VERSION "BYD N3 (SA6) subset of ADC V2.8.0 20251225 platform matrices"

NS_ :

BS_:

BU_: XXX

BO_ 109 EPS_0x06D: 64 EPS
SG_ Counter_06D_S : 0|16@1+ (1,0) [0E-008|65535.00000000] "" ADC
SG_ Checksum_06D_S : 16|16@1+ (1,0) [0E-008|65535.00000000] "" ADC
SG_ EPS_AgCtrlAvl : 32|2@1+ (1,0) [0E-008|3.00000000] "" ADC
SG_ EPS_AgCtrlSts : 34|2@1+ (1,0) [0E-008|3.00000000] "" ADC
SG_ EPS_TqCtrlAvl : 36|2@1+ (1,0) [0E-008|3.00000000] "" ADC
SG_ EPS_TqCtrlSts : 38|2@1+ (1,0) [0E-008|3.00000000] "" ADC
SG_ EPS_LdwWarnAvl : 40|2@1+ (1,0) [0E-008|3.00000000] "" ADC
SG_ EPS_LdwWarnSts : 42|2@1+ (1,0) [0E-008|3.00000000] "" ADC
SG_ EPS_SteerPinionAg : 44|16@1- (0.1000000000000000055511151231257827021181583404541015625,0) [-720.00000000|720.00000000] "deg" ADC
SG_ EPS_SteerPinionAgVld : 60|1@1+ (1,0) [0E-008|1.00000000] "" ADC
SG_ EPS_SteerPinionAgRat : 61|15@1- (0.1000000000000000055511151231257827021181583404541015625,0) [-1500.00000000|1500.00000000] "deg/s" ADC
SG_ EPS_SteerPinionAgRatVld : 76|1@1+ (1,0) [0E-008|1.00000000] "" ADC
SG_ EPS_SteerWheelAg : 77|16@1- (0.1000000000000000055511151231257827021181583404541015625,0) [-720.00000000|720.00000000] "deg" ADC
SG_ EPS_SteerWheelAgVld : 93|1@1+ (1,0) [0E-008|1.00000000] "" ADC
SG_ EPS_SteerWheelAgRat : 94|15@1- (0.1000000000000000055511151231257827021181583404541015625,0) [-1500.00000000|1500.00000000] "deg/s" ADC
SG_ EPS_SteerWheelAgRatVld : 109|1@1+ (1,0) [0E-008|1.00000000] "" ADC
SG_ EPS_AsscMotCrtTq : 110|11@1- (0.0200000000000000004163336342344337026588618755340576171875,0) [-20.00000000|20.00000000] "Nm" ADC
SG_ EPS_AsscMotCrtTqVld : 121|1@1+ (1,0) [0E-008|1.00000000] "" ADC
SG_ EPS_DrvrSteerTq : 122|11@1- (0.0200000000000000004163336342344337026588618755340576171875,0) [-20.00000000|20.00000000] "Nm" ADC
SG_ EPS_DrvrSteerTqVld : 133|1@1+ (1,0) [0E-008|1.00000000] "-" ADC
SG_ EPS_DrvrSteerTqFlt : 134|11@1- (0.0200000000000000004163336342344337026588618755340576171875,0) [-20.00000000|20.00000000] "Nm" ADC
SG_ EPS_DrvrSteerTqFltVld : 145|1@1+ (1,0) [0E-008|1.00000000] "-" ADC
SG_ EPS_SteerDrvrOvrd : 146|1@1+ (1,0) [0E-008|1.00000000] "" ADC
SG_ EPS_SteerDrvrOvrdVld : 147|1@1+ (1,0) [0E-008|1.00000000] "" ADC
SG_ EPS_ADCReqErrorFb : 148|3@1+ (1,0) [0E-008|7.00000000] "" ADC
SG_ EPS_AbortFb : 151|3@1+ (1,0) [0E-008|7.00000000] "" ADC
SG_ EPS_SteerMod : 154|3@1+ (1,0) [0E-008|7.00000000] "" ADC
SG_ EpsFltSts : 157|2@1+ (1,0) [0E-008|3.00000000] "" ADC
SG_ EPS_BoostMod : 159|2@1+ (1,0) [0E-008|3.00000000] "" ADC
SG_ EPS_TasCalSts : 161|1@1+ (1,0) [0E-008|1.00000000] "" ADC
SG_ EPS_Tq1 : 162|11@1- (0.0200000000000000004163336342344337026588618755340576171875,0) [-20.00000000|20.00000000] "Nm" ADC
SG_ EPS_Tq2 : 173|11@1- (0.0200000000000000004163336342344337026588618755340576171875,0) [-20.00000000|20.00000000] "Nm" ADC
SG_ EPS_Fastbattery_Temperature : 184|11@1+ (0.200000000000000011102230246251565404236316680908203125,-60) [-60.00000000|349.40000000] "°" ADC
BO_ 268 IPB_0x10C: 64 IPB
SG_ Checksum_10C_S : 0|16@1+ (1,0) [0E-008|65535.00000000] "" ADC
SG_ Counter_10C_S : 16|16@1+ (1,0) [0E-008|65535.00000000] "" ADC
SG_ Vehicle_speed : 35|12@1+ (0.0687500000000000055511151231257827021181583404541015625,0) [0E-008|281.46250000] "km/h" ADC
SG_ VehicleSpeed_Status : 47|1@1+ (1,0) [0E-008|1.00000000] "" ADC
SG_ WheelSpeed_FL : 48|12@1+ (0.0687500000000000055511151231257827021181583404541015625,0) [0E-008|281.46250000] "km/h" ADC
SG_ WheelSpeed_FR : 60|12@1+ (0.0687500000000000055511151231257827021181583404541015625,0) [0E-008|281.46250000] "km/h" ADC
SG_ WheelSpeed_RL : 72|12@1+ (0.0687500000000000055511151231257827021181583404541015625,0) [0E-008|281.46250000] "km/h" ADC
SG_ WheelSpeed_RR : 84|12@1+ (0.0687500000000000055511151231257827021181583404541015625,0) [0E-008|281.46250000] "km/h" ADC
SG_ WheelSpeed_FR_Status : 96|1@1+ (1,0) [0E-008|1.00000000] "" ADC
SG_ WheelSpeed_FL_Status : 97|1@1+ (1,0) [0E-008|1.00000000] "" ADC
SG_ WheelSpeed_RR_Status : 98|1@1+ (1,0) [0E-008|1.00000000] "" ADC
SG_ WheelSpeed_RL_Status : 99|1@1+ (1,0) [0E-008|1.00000000] "" ADC
SG_ RRWheelDriveDirection : 100|2@1+ (1,0) [0E-008|3.00000000] "" ADC
SG_ RLWheelDriveDirection : 102|2@1+ (1,0) [0E-008|3.00000000] "" ADC
SG_ FRWheelDriveDirection : 104|2@1+ (1,0) [0E-008|3.00000000] "" ADC
SG_ FLWheelDriveDirection : 106|2@1+ (1,0) [0E-008|3.00000000] "" ADC
SG_ FLWheelDriveDirectionStatus : 108|1@1+ (1,0) [0E-008|1.00000000] "" ADC
SG_ FRWheelDriveDirectionStatus : 109|1@1+ (1,0) [0E-008|1.00000000] "" ADC
SG_ RLWheelDriveDirectionStatus : 110|1@1+ (1,0) [0E-008|1.00000000] "" ADC
SG_ RRWheelDriveDirectionStatus : 111|1@1+ (1,0) [0E-008|1.00000000] "" ADC
SG_ FLWheelPulseCounter : 112|10@1+ (1,0) [0E-008|1022.00000000] "" ADC
SG_ FRWheelPulseCounter : 122|10@1+ (1,0) [0E-008|1022.00000000] "" ADC
SG_ RLWheelPulseCounter : 132|10@1+ (1,0) [0E-008|1022.00000000] "" ADC
SG_ RRWheelPulseCounter : 142|10@1+ (1,0) [0E-008|1022.00000000] "" ADC
SG_ RRWheelPulseCounterValidity : 152|1@1+ (1,0) [0E-008|1.00000000] "" ADC
SG_ RLWheelPulseCounterValidity : 153|1@1+ (1,0) [0E-008|1.00000000] "" ADC
SG_ FRWheelPulseCounterValidity : 154|1@1+ (1,0) [0E-008|1.00000000] "" ADC
SG_ FLWheelPulseCounterValidity : 155|1@1+ (1,0) [0E-008|1.00000000] "" ADC
SG_ EBD_Active : 156|1@1+ (1,0) [0E-008|1.00000000] "" ADC
SG_ EBD_Fault : 157|1@1+ (1,0) [0E-008|1.00000000] "" ADC
SG_ ABS_Active : 158|1@1+ (1,0) [0E-008|1.00000000] "" ADC
SG_ ABS_Fault : 159|1@1+ (1,0) [0E-008|1.00000000] "" ADC
SG_ VDC_Active : 160|1@1+ (1,0) [0E-008|1.00000000] "" ADC
SG_ VDC_Fault : 161|1@1+ (1,0) [0E-008|1.00000000] "" ADC
SG_ ESP_OFF : 162|1@1+ (1,0) [0E-008|1.00000000] "" ADC
SG_ ESP_Active : 163|1@1+ (1,0) [0E-008|1.00000000] "" ADC
SG_ TCS_Fault : 164|1@1+ (1,0) [0E-008|1.00000000] "" ADC
SG_ AVH_CtrlStatus : 166|2@1+ (1,0) [0E-008|3.00000000] "" ADC
SG_ LFI_Longitudinal_Torque_Interface_Function_Execution_Estimate_S : 168|16@1+ (1,-30000) [-30000.00000000|30000.00000000] "" ADC
SG_ DiDyna_Estimate_Yaw_Torque : 184|16@1+ (2,-40000) [-40000.00000000|40000.00000000] "" ADC
SG_ TCS_Active : 209|1@1+ (1,0) [0E-008|1.00000000] "" ADC
SG_ CCO_Active : 210|2@1+ (1,0) [0E-008|3.00000000] "" ADC
SG_ HDC_CtrlStatus : 222|2@1+ (1,0) [0E-008|3.00000000] "" ADC
SG_ Yaw_Rate : 225|12@1+ (0.0021326029999999998425230796073037708993069827556610107421875,-2.094300000000000050448534238967113196849822998046875) [-2.09430000|2.09430000] "rad/s" ADC
SG_ Yaw_Rate_Offset : 237|12@1+ (0.0021326029999999998425230796073037708993069827556610107421875,-0.13000000000000000444089209850062616169452667236328125) [-0.13000000|0.13000000] "rad/s" ADC
SG_ Yaw_Rate_Status : 249|1@1+ (1,0) [0E-008|1.00000000] "" ADC
SG_ AX : 250|12@1+ (0.02712673599999999851650755999799002893269062042236328125,-21.592999999999999971578290569595992565155029296875) [-21.59300000|21.59300000] "m/s�0�5" ADC
SG_ AX_Offset : 262|12@1+ (0.02712673599999999851650755999799002893269062042236328125,-21.592999999999999971578290569595992565155029296875) [-21.59300000|21.59300000] "m/s�0�5" ADC
SG_ AXstatus : 274|1@1+ (1,0) [0E-008|1.00000000] "" ADC
SG_ AY : 275|12@1+ (0.02712673599999999851650755999799002893269062042236328125,-21.592999999999999971578290569595992565155029296875) [-21.59300000|21.59300000] "m/s�0�5" ADC
SG_ AYOffset : 287|12@1+ (0.02712673599999999851650755999799002893269062042236328125,-21.592999999999999971578290569595992565155029296875) [-21.59300000|21.59300000] "m/s�0�5" ADC
SG_ AYstatus : 299|1@1+ (1,0) [0E-008|1.00000000] "" ADC
SG_ AutomaticBrakingAvailable : 303|1@1+ (1,0) [0E-008|1.00000000] "" ADC
SG_ AutomaticBrakingActive : 304|1@1+ (1,0) [0E-008|1.00000000] "" ADC
SG_ IPB_InputRodStroke : 306|10@1+ (0.05000000000000000277555756156289135105907917022705078125,-5) [-5.00000000|46.15000000] "mm" ADC
SG_ IPB_InputRodStroke_Status : 316|1@1+ (1,0) [0E-008|1.00000000] "" ADC
SG_ FWA_warning : 318|2@1+ (1,0) [0E-008|3.00000000] "" ADC
SG_ DiDyna_LDI_Active : 320|1@1+ (1,0) [0E-008|1.00000000] "" ADC
SG_ Basc_FA : 323|1@1+ (1,0) [0E-008|1.00000000] "" ADC
SG_ Basc_RA : 324|1@1+ (1,0) [0E-008|1.00000000] "" ADC
SG_ AWBavailable : 325|1@1+ (1,0) [0E-008|1.00000000] "" ADC
SG_ AWBactive : 326|1@1+ (1,0) [0E-008|1.00000000] "" ADC
SG_ PrefillAvailable : 330|1@1+ (1,0) [0E-008|1.00000000] "" ADC
SG_ PrefillActive : 331|1@1+ (1,0) [0E-008|1.00000000] "" ADC
SG_ ESC_BrkTqCtrlAvlDriving : 335|1@1+ (1,0) [0E-008|1.00000000] "" ADC
SG_ ESC_BrkTqCtrlAvlParking : 336|2@1+ (1,0) [0E-008|3.00000000] "" ADC
SG_ ESC_BrkTqCtrlActv : 338|2@1+ (1,0) [0E-008|3.00000000] "" ADC
SG_ ESC_AebBrkTqAvl : 340|1@1+ (1,0) [0E-008|1.00000000] "" ADC
SG_ IPB_BRAKE_PEDAL_STARUS : 349|2@1+ (1,0) [0E-008|3.00000000] "" ADC
SG_ IPB_SimulatorPressure_Sts : 351|1@1+ (1,0) [0E-008|1.00000000] "" ADC
SG_ IPB_SimulatorPressure : 352|12@1+ (0.299999999999999988897769753748434595763683319091796875,-5) [-5.00000000|301.90000000] "bar" ADC
SG_ IPB_PlungerPressure_status : 364|1@1+ (1,0) [0E-008|1.00000000] "" ADC
SG_ DiDyna_LDI_Available : 365|1@1+ (1,0) [0E-008|1.00000000] "" ADC
SG_ IPB_PlungerPressure : 366|12@1+ (0.299999999999999988897769753748434595763683319091796875,-5) [-5.00000000|301.90000000] "bar" ADC
SG_ Ve_Target_Fdback_Tor_Flag_S : 378|2@1+ (1,0) [0E-008|3.00000000] "" ADC
SG_ Ve_Target_Fdback_Tor_S : 380|14@1+ (1,-6000) [-6000.00000000|6000.00000000] "NM" ADC
SG_ ESC_DrvrTqDes : 408|16@1+ (1,-30000) [-30000.00000000|-30000.00000000] "" ADC
SG_ ESC_HydBrkActvTq : 424|16@1+ (1,-30000) [-30000.00000000|-30000.00000000] "" ADC
SG_ MMotTarFast_FA : 440|16@1+ (1,-12000) [-12000.00000000|12000.00000000] "" ADC
SG_ MMotTarFast_RA : 456|16@1+ (1,-12000) [-12000.00000000|12000.00000000] "" ADC
SG_ MMotInc_FA_S : 472|14@1+ (1,-6000) [-6000.00000000|6000.00000000] "" ADC
SG_ MMotInc_RA_S : 486|14@1+ (1,-6000) [-6000.00000000|6000.00000000] "" ADC
SG_ IPB_BrakeOverride_val : 500|1@1+ (1,0) [0E-008|1.00000000] "" ADC
SG_ IPB_BrakeOverride : 501|1@1+ (1,0) [0E-008|1.00000000] "" ADC
SG_ HHC_Active : 503|1@1+ (1,0) [0E-008|1.00000000] "" ADC
SG_ ESC_AebBrkTqActv : 504|1@1+ (1,0) [0E-008|1.00000000] "" ADC
SG_ VehicleStandstill : 505|2@1+ (1,0) [0E-008|3.00000000] "" ADC
SG_ BMsr_FA_S : 509|1@1+ (1,0) [0E-008|1.00000000] "" ADC
SG_ BMsr_RA_S : 510|1@1+ (1,0) [0E-008|1.00000000] "" ADC
BO_ 90 VCU_0x05A: 64 VCU
SG_ Checksum_05A_S : 0|16@1+ (1,0) [0E-008|65535.00000000] "" ADC
SG_ Counter_05A_S : 16|16@1+ (1,0) [0E-008|65535.00000000] "" ADC
SG_ VCU_ActPedlPosnVld : 32|1@1+ (1,0) [0E-008|1.00000000] "" ADC
SG_ VCU_AccrPedlPosnVld : 33|1@1+ (1,0) [0E-008|1.00000000] "" ADC
SG_ VCU_DrvrAccrPedlOvrd : 34|1@1+ (1,0) [0E-008|1.00000000] "" ADC
SG_ VCU_DrvrAccrPedlOvrdVLD : 35|1@1+ (1,0) [0E-008|1.00000000] "" ADC
SG_ VCU_VehWhlActTqVld : 36|1@1+ (1,0) [0E-008|1.00000000] "" ADC
SG_ VCU_FrntWhlReqTqVld : 37|1@1+ (1,0) [0E-008|1.00000000] "" ADC
SG_ VCU_ReWhlReqTqVld : 38|1@1+ (1,0) [0E-008|1.00000000] "" ADC
SG_ VCU_VehWhlReqTqVld : 39|1@1+ (1,0) [0E-008|1.00000000] "" ADC
SG_ VCU_DriverTorqueDesired : 40|16@1- (1,0) [-32768.00000000|32767.00000000] "" ADC
SG_ VCU_OrgDriverTorqueDesired : 56|16@1- (1,0) [-32768.00000000|32767.00000000] "" ADC
SG_ VCU_VehWhlActTq : 72|16@1- (1,0) [-32768.00000000|32767.00000000] "" ADC
SG_ VCU_FrntWhlReqTq : 88|16@1- (1,0) [-32768.00000000|32767.00000000] "" ADC
SG_ VCU_ReWhlReqTq : 104|16@1- (1,0) [-32768.00000000|32767.00000000] "" ADC
SG_ VCU_VehWhlReqTq : 120|16@1- (1,0) [-32768.00000000|32767.00000000] "" ADC
SG_ VCU_PtRgnTqMax : 136|16@1- (1,0) [-32768.00000000|32767.00000000] "" ADC
SG_ VCU_PtElecTqMax : 152|16@1- (1,0) [-32768.00000000|32767.00000000] "" ADC
SG_ VCU_MotorRegenTorqueLmtInD : 168|13@1- (1,0) [-4096.00000000|4095.00000000] "" ADC
SG_ VCU_PtRgnTqMaxVld : 181|1@1+ (1,0) [0E-008|1.00000000] "" ADC
SG_ VCU_PtElecTqMaxVld : 182|1@1+ (1,0) [0E-008|1.00000000] "" ADC
SG_ VCU_MotorRegenTrqLmtInDValid : 183|1@1+ (1,0) [0E-008|1.00000000] "" ADC
SG_ VCU_PtTqAvl : 184|2@1+ (1,0) [0E-008|3.00000000] "" ADC
SG_ VCU_PtTqActvSts : 186|1@1+ (1,0) [0E-008|1.00000000] "" ADC
SG_ VCU_MCUModActvSt : 187|2@1+ (1,0) [0E-008|3.00000000] "" ADC
SG_ VCU_MCUBlkSt : 189|3@1+ (1,0) [0E-008|7.00000000] "" ADC
SG_ VCU_SpdSvModAvl : 192|1@1+ (1,0) [0E-008|1.00000000] "" ADC
SG_ VCU_MCUStandstill : 193|1@1+ (1,0) [0E-008|1.00000000] "" ADC
SG_ VCU_MCUSpdSVModFlt : 194|3@1+ (1,0) [0E-008|7.00000000] "" ADC
SG_ VCU_ErrorFb : 197|4@1+ (1,0) [0E-008|15.00000000] "" ADC
SG_ VCU_MCUReqTq : 201|14@1- (1,0) [-5001.00000000|5001.00000000] "" ADC
SG_ Rnk_efc_flg_hw : 215|1@1+ (1,0) [0E-008|1.00000000] "" ADC
SG_ VCU_MCUActRUnfilteredRodSpd : 216|16@1- (1,0) [-30001.00000000|3001.00000000] "rpm" ADC
SG_ VCU_MCUActFUnfilteredRodSpd : 232|16@1- (1,0) [-30001.00000000|3001.00000000] "rpm" ADC
SG_ Rnk_hw : 248|4@1+ (1,0) [0E-008|15.00000000] "" ADC
SG_ F_mot_spd_err_flg_hw : 252|1@1+ (1,0) [0E-008|1.00000000] "" ADC
SG_ R_mot_spd_err_hw : 253|1@1+ (1,0) [0E-008|1.00000000] "" ADC
SG_ Faxis_act_tq_efc_flg_hw : 254|1@1+ (1,0) [0E-008|1.00000000] "" ADC
SG_ R_mot_fac_tq_sts_hw : 255|1@1+ (1,0) [0E-008|1.00000000] "" ADC
SG_ Act_acce_pedl_perc_hw : 256|8@1+ (1,0) [0E-008|100.00000000] "" ADC
SG_ F_mot_spd_hw : 264|16@1+ (1,-30000) [-30000.00000000|30000.00000000] "" ADC
SG_ R_mot_spd_hw : 280|16@1+ (1,-30000) [-30000.00000000|30000.00000000] "" ADC
SG_ Act_drv_mod_hw : 296|8@1+ (1,0) [0E-008|255.00000000] "" ADC
SG_ Virt_acce_pedl_perc_hw : 304|8@1+ (1,0) [0E-008|100.00000000] "" ADC
SG_ Faxis_act_tq_hw : 312|16@1+ (1,-12000) [-12000.00000000|12000.00000000] "" ADC
SG_ R_axis_fac_tq_hw : 328|16@1+ (1,-12000) [-12000.00000000|12000.00000000] "" ADC
SG_ Ok_lamp_hw : 344|2@1+ (1,0) [0E-008|3.00000000] "" ADC
SG_ VCU_DriveReady : 346|2@1+ (1,0) [0E-008|3.00000000] "" ADC
SG_ Bsg_Gmcu_start_eng_sts : 348|2@1+ (1,0) [0E-008|3.00000000] "" ADC
SG_ VCU_REQ_ADAS_SPC_FUN_STOP_EN_S : 350|2@1+ (1,0) [0E-008|3.00000000] "" ADC
SG_ FL_mot_whl_act_tq_S : 352|16@1- (1,0) [-32768.00000000|32767.00000000] "Nm" ADC
SG_ FR_mot_whl_act_tq_S : 368|16@1- (1,0) [-32768.00000000|32767.00000000] "Nm" ADC
SG_ RL_mot_whl_act_tq_S : 384|16@1- (1,0) [-32768.00000000|32767.00000000] "Nm" ADC
SG_ RR_mot_whl_act_tq_S : 400|16@1- (1,0) [-32768.00000000|32767.00000000] "Nm" ADC
SG_ FL_mot_spd_S : 416|16@1- (1,0) [-32768.00000000|32767.00000000] "Nm" ADC
SG_ FR_mot_spd_S : 432|16@1- (1,0) [-32768.00000000|32767.00000000] "Nm" ADC
SG_ RL_mot_spd_S : 448|16@1- (1,0) [-32768.00000000|32767.00000000] "Nm" ADC
SG_ RR_mot_spd_S : 464|16@1- (1,0) [-32768.00000000|32767.00000000] "Nm" ADC
SG_ FL_mot_whl_act_tq_efc_flg_S : 480|1@1+ (1,0) [0E-008|1.00000000] "" ADC
SG_ FR_mot_whl_act_tq_efc_flg_S : 481|1@1+ (1,0) [0E-008|1.00000000] "" ADC
SG_ LR_mot_whl_act_tq_efc_flg_S : 482|1@1+ (1,0) [0E-008|1.00000000] "" ADC
SG_ RR_mot_whl_act_tq_efc_flg_S : 483|1@1+ (1,0) [0E-008|1.00000000] "" ADC
SG_ FL_mot_spd_efc_flg_S : 484|1@1+ (1,0) [0E-008|1.00000000] "" ADC
SG_ FR_mot_spd_efc_flg_S : 485|1@1+ (1,0) [0E-008|1.00000000] "" ADC
SG_ RL_mot_spd_efc_flg_S : 486|1@1+ (1,0) [0E-008|1.00000000] "" ADC
SG_ RR_mot_spd_efc_flg_S : 487|1@1+ (1,0) [0E-008|1.00000000] "" ADC
SG_ AI_Drift_Control_Mode_Response_State_S : 488|1@1+ (1,0) [0E-008|1.00000000] "" ADC
SG_ E4_ParkEPS_Contrl_Learning_S : 496|2@1+ (1,0) [0E-008|3.00000000] "" ADC
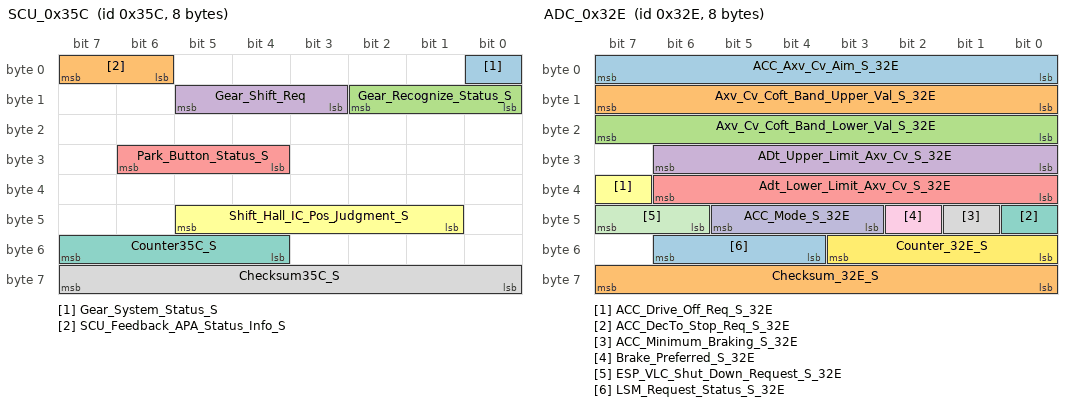
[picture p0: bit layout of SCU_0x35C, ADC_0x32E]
BO_ 860 SCU_0x35C: 8 SCU
SG_ Gear_System_Status_S : 0|1@1+ (1,0) [0E-008|1.00000000] "" ADC
SG_ SCU_Feedback_APA_Status_Info_S : 6|2@1+ (1,0) [0E-008|3.00000000] "" ADC
SG_ Gear_Recognize_Status_S : 8|3@1+ (1,0) [0E-008|7.00000000] "" ADC
SG_ Gear_Shift_Req : 11|3@1+ (1,0) [0E-008|7.00000000] "" ADC
SG_ Park_Button_Status_S : 28|3@1+ (1,0) [0E-008|7.00000000] "" ADC
SG_ Shift_Hall_IC_Pos_Judgment_S : 41|5@1+ (1,0) [0E-008|31.00000000] "" ADC
SG_ Counter35C_S : 52|4@1+ (1,0) [0E-008|15.00000000] "Nm" ADC
SG_ Checksum35C_S : 56|8@1+ (1,0) [0E-008|255.00000000] "度" ADC
BO_ 813 ADC_0x32D: 8 ADC
SG_ Set_Speed_S : 0|9@1+ (1,0) [0E-008|255.50000000] "" Left_BCM,Media,INS,SRS,FCR
SG_ Obj_Valid_S : 9|1@1+ (1,0) [0E-008|1.00000000] "" Left_BCM,Media,INS,SRS,FCR
SG_ Tau_Gap_Set_S : 10|3@1+ (1,0) [0E-008|7.00000000] "" Left_BCM,Media,INS,SRS,FCR
SG_ Dx_Tar_Obj_S : 13|3@1+ (1,0) [0E-008|7.00000000] "" Left_BCM,Media,INS,SRS,FCR
SG_ PCW_Pre_Warning_S : 16|1@1+ (1,0) [0E-008|1.00000000] "" Left_BCM,Media,INS,SRS,FCR
SG_ PCW_Latent_Warning_S : 17|1@1+ (1,0) [0E-008|1.00000000] "" Left_BCM,Media,INS,SRS,FCR
SG_ PCW_State_S : 18|1@1+ (1,0) [0E-008|1.00000000] "" Left_BCM,Media,INS,SRS,FCR
SG_ ACC_Mode_Display_S : 19|3@1+ (1,0) [0E-008|7.00000000] "" Left_BCM,Media,INS,SRS,FCR
SG_ ACC_State_S : 22|1@1+ (1,0) [0E-008|1.00000000] "" Left_BCM,Media,INS,SRS,FCR
SG_ Take_Over_Req_S : 23|1@1+ (1,0) [0E-008|1.00000000] "" Left_BCM,Media,INS,SRS,FCR
SG_ Speed_Unit_Set_S2 : 24|2@1+ (1,0) [0E-008|3.00000000] "" Left_BCM,Media,INS,SRS,FCR
SG_ CCR_AEB_Error_S : 26|1@1+ (1,0) [0E-008|1.00000000] "" Left_BCM,Media,INS,SRS,FCR
SG_ ACC_Text_Info_For_Driver_S : 27|5@1+ (1,0) [0E-008|31.00000000] "" Left_BCM,Media,INS,SRS,FCR
SG_ CCR_FCW_Error_S : 32|1@1+ (1,0) [0E-008|1.00000000] "" Left_BCM,Media,INS,SRS,FCR
SG_ Pedestrian_FCW_Brak_Error_S : 33|1@1+ (1,0) [0E-008|1.00000000] "" Left_BCM,Media,INS,SRS,FCR
SG_ Acute_Warning_S : 35|1@1+ (1,0) [0E-008|1.00000000] "" Left_BCM,Media,INS,SRS,FCR
SG_ AEB_State_S : 36|1@1+ (1,0) [0E-008|1.00000000] "" Left_BCM,Media,INS,SRS,FCR
SG_ PCWLevelState : 37|2@1+ (1,0) [0E-008|3.00000000] "" Left_BCM,Media,INS,SRS,FCR
SG_ Front_radar_FCTB_Warning : 41|3@1+ (1,0) [0E-008|7.00000000] "" Left_BCM,Media,INS,SRS,FCR
SG_ ACC_Mode_Display1_S : 44|4@1+ (1,0) [0E-008|15.00000000] "" Left_BCM,Media,INS,SRS,FCR
SG_ Counter_32D_S : 48|4@1+ (1,0) [0E-008|15.00000000] "" Left_BCM,Media,INS,SRS,FCR
SG_ ELK_Assemble_Status_S : 52|1@1+ (1,0) [0E-008|1.00000000] "" Left_BCM,Media,INS,SRS,FCR
SG_ MRR_Modulation_Status : 54|2@1+ (1,0) [0E-008|3.00000000] "" Left_BCM,Media,INS,SRS,FCR
SG_ Checksum_32D_S : 56|8@1+ (1,0) [0E-008|255.00000000] "" Left_BCM,Media,INS,SRS,FCR
BO_ 814 ADC_0x32E: 8 ADC
SG_ ACC_Axv_Cv_Aim_S_32E : 0|8@1+ (0.05000000000000000277555756156289135105907917022705078125,-7) [-7.00000000|5.75000000] "m/s2" VCU,IPB
SG_ Axv_Cv_Coft_Band_Upper_Val_S_32E : 8|8@1+ (0.05000000000000000277555756156289135105907917022705078125,-7) [-7.00000000|5.75000000] "m/s2" VCU,IPB
SG_ Axv_Cv_Coft_Band_Lower_Val_S_32E : 16|8@1+ (0.05000000000000000277555756156289135105907917022705078125,-7) [-7.00000000|5.75000000] "m/s2" VCU,IPB
SG_ ADt_Upper_Limit_Axv_Cv_S_32E : 24|7@1+ (0.200000000000000011102230246251565404236316680908203125,0) [0E-008|16.00000000] "m/s3" VCU,IPB
SG_ Adt_Lower_Limit_Axv_Cv_S_32E : 32|7@1+ (0.200000000000000011102230246251565404236316680908203125,-16) [-16.00000000|0E-008] "m/s3" VCU,IPB
SG_ ACC_Drive_Off_Req_S_32E : 39|1@1+ (1,0) [0E-008|1.00000000] "" VCU,IPB
SG_ ACC_DecTo_Stop_Req_S_32E : 40|1@1+ (1,0) [0E-008|1.00000000] "" VCU,IPB
SG_ ACC_Minimum_Braking_S_32E : 41|1@1+ (1,0) [0E-008|1.00000000] "" VCU,IPB
SG_ Brake_Preferred_S_32E : 42|1@1+ (1,0) [0E-008|1.00000000] "" VCU,IPB
SG_ ACC_Mode_S_32E : 43|3@1+ (1,0) [0E-008|7.00000000] "" VCU,IPB,SRS
SG_ ESP_VLC_Shut_Down_Request_S_32E : 46|2@1+ (1,0) [0E-008|3.00000000] "" VCU,IPB
SG_ Counter_32E_S : 48|4@1+ (1,0) [0E-008|15.00000000] "" VCU,IPB
SG_ LSM_Request_Status_S_32E : 52|3@1+ (1,0) [0E-008|7.00000000] "" VCU,IPB
SG_ Checksum_32E_S : 56|8@1+ (1,0) [0E-008|255.00000000] "" VCU,IPB
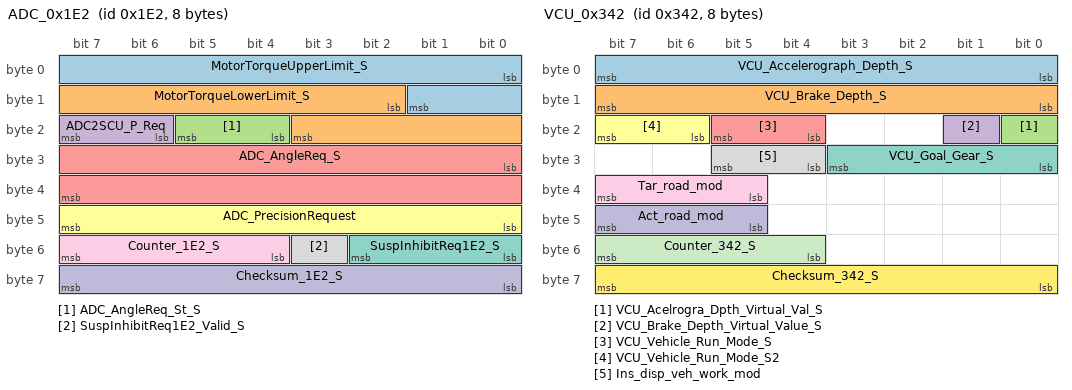
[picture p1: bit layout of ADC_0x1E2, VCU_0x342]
BO_ 482 ADC_0x1E2: 8 ADC
SG_ MotorTorqueUpperLimit_S : 0|10@1+ (0.01000000000000000020816681711721685132943093776702880859375,0) [0E-008|5.00000000] "" Left_BCM,VCU,DiSus
SG_ MotorTorqueLowerLimit_S : 10|10@1- (0.01000000000000000020816681711721685132943093776702880859375,0) [-5.00000000|0E-008] "" Left_BCM,VCU,DiSus
SG_ ADC_AngleReq_St_S : 20|2@1+ (1,0) [0E-008|3.00000000] "" Left_BCM,VCU,DiSus
SG_ ADC2SCU_P_Req : 22|2@1+ (1,0) [0E-008|3.00000000] "" Left_BCM,VCU,DiSus
SG_ ADC_AngleReq_S : 24|16@1- (0.1000000000000000055511151231257827021181583404541015625,0) [-780.00000000|779.90000000] "" Left_BCM,VCU,DiSus
SG_ ADC_PrecisionRequest : 40|8@1+ (1,0) [0E-008|100.00000000] "%" Left_BCM,VCU,DiSus
SG_ SuspInhibitReq1E2_S : 48|3@1+ (1,0) [0E-008|7.00000000] "" Left_BCM,VCU,DiSus
SG_ SuspInhibitReq1E2_Valid_S : 51|1@1+ (1,0) [0E-008|1.00000000] "" Left_BCM,VCU,DiSus
SG_ Counter_1E2_S : 52|4@1+ (1,0) [0E-008|15.00000000] "" Left_BCM,VCU,DiSus
SG_ Checksum_1E2_S : 56|8@1+ (1,0) [0E-008|255.00000000] "" Left_BCM,VCU,DiSus
BO_ 790 ADC_0x316: 8 ADC
SG_ HMA_Stats_S_316 : 0|3@1+ (1,0) [0E-008|7.00000000] "" Left_BCM,Media,INFC,INS,SWS,SCPA,EPS,MSR_DRV
SG_ HMA_High_Beam_Request_S_316 : 3|1@1+ (1,0) [0E-008|1.00000000] "" Left_BCM,Media,INFC,INS,SWS,SCPA,EPS,MSR_DRV
SG_ Left_Line_Tracking_Status_S : 4|2@1+ (1,0) [0E-008|3.00000000] "" Left_BCM,Media,INFC,INS,SWS,SCPA,EPS,MSR_DRV
SG_ Lane_Assistant_Mode_Status_S : 6|2@1+ (1,0) [0E-008|3.00000000] "" Left_BCM,Media,INFC,INS,SWS,SCPA,EPS,MSR_DRV
SG_ LKS_Sensitivity_S : 8|2@1+ (1,0) [0E-008|3.00000000] "" Left_BCM,Media,INFC,INS,SWS,SCPA,EPS,MSR_DRV
SG_ LDP_LDW_Camera_Blocked_S : 11|1@1+ (1,0) [0E-008|1.00000000] "" Left_BCM,Media,INFC,INS,SWS,SCPA,EPS,MSR_DRV
SG_ LDP_Fault_S : 12|1@1+ (1,0) [0E-008|1.00000000] "" Left_BCM,Media,INFC,INS,SWS,SCPA,EPS,MSR_DRV
SG_ LDW_fault1_S : 13|1@1+ (1,0) [0E-008|1.00000000] "" Left_BCM,Media,INFC,INS,SWS,SCPA,EPS,MSR_DRV
SG_ ACC_AEB_Camera_Blocked_Infro_S : 14|1@1+ (1,0) [0E-008|1.00000000] "" Left_BCM,Media,INFC,INS,SWS,SCPA,EPS,MSR_DRV
SG_ Over_Temperature : 15|1@1+ (1,0) [0E-008|1.00000000] "" Left_BCM,Media,INFC,INS,SWS,SCPA,EPS,MSR_DRV
SG_ Output_LKS_torque_request_S : 16|11@1- (0.01000000000000000020816681711721685132943093776702880859375,0) [-10.24000000|10.23000000] "Nm" Left_BCM,Media,INFC,INS,SWS,SCPA,EPS,MSR_DRV
SG_ LKS_torque_request_staus_S : 27|2@1+ (1,0) [0E-008|3.00000000] "" Left_BCM,Media,INFC,INS,SWS,SCPA,EPS,MSR_DRV
SG_ LDP_New_Take_Over_Req_S : 29|3@1+ (1,0) [0E-008|7.00000000] "" Left_BCM,Media,INFC,INS,SWS,SCPA,EPS,MSR_DRV
SG_ RSF_Output_Speed_Limit_Unit_S : 32|2@1+ (1,0) [0E-008|3.00000000] "" Left_BCM,Media,INFC,INS,SWS,SCPA,EPS,MSR_DRV
SG_ Right_Line_Tracking_Stats_S : 34|2@1+ (1,0) [0E-008|3.00000000] "" Left_BCM,Media,INFC,INS,SWS,SCPA,EPS,MSR_DRV
SG_ TJA_ICA_function_status_S : 36|3@1+ (1,0) [0E-008|7.00000000] "" Left_BCM,Media,INFC,INS,SWS,SCPA,EPS,MSR_DRV
SG_ ALL_Function_Camera_Bloc_Infro_S : 39|1@1+ (1,0) [0E-008|1.00000000] "" Left_BCM,Media,INFC,INS,SWS,SCPA,EPS,MSR_DRV
SG_ RSF_Output_Speed_Limit_S : 40|8@1+ (1,0) [0E-008|255.00000000] "" Left_BCM,Media,INFC,INS,SWS,SCPA,EPS,MSR_DRV
SG_ LDW_Warning_Mode_Stats_S : 48|2@1+ (1,0) [0E-008|3.00000000] "" Left_BCM,Media,INFC,INS,SWS,SCPA,EPS,MSR_DRV
SG_ ADC_Take_Over_Req1_S : 50|2@1+ (1,0) [0E-008|3.00000000] "" Left_BCM,Media,INFC,INS,SWS,SCPA,EPS,MSR_DRV
SG_ Counter_316_S : 52|4@1+ (1,0) [0E-008|15.00000000] "" Left_BCM,Media,INFC,INS,SWS,SCPA,EPS,MSR_DRV
SG_ Checksum_316_S : 56|8@1+ (1,0) [0E-008|255.00000000] "" Left_BCM,Media,INFC,INS,SWS,SCPA,EPS,MSR_DRV
BO_ 834 VCU_0x342: 8 VCU
SG_ VCU_Accelerograph_Depth_S : 0|8@1+ (1,0) [0E-008|100.00000000] "%" Left_BCM,Right_BCM,Rear_BCM,LTE4G,CS,SRS,ADC,MRR,LRCR,RRCR,FCR,MSR_DRV
SG_ VCU_Brake_Depth_S : 8|8@1+ (1,0) [0E-008|100.00000000] "%" LTE4G,CS,ECM,ECM_Fuel,ADC,MRR,LRCR,RRCR,APA,FLL
SG_ VCU_Acelrogra_Dpth_Virtual_Val_S : 16|1@1+ (1,0) [0E-008|1.00000000] "" LTE4G,SRS,ADC,MRR,LRCR,RRCR,FCR,MSR_DRV
SG_ VCU_Brake_Depth_Virtual_Value_S : 17|1@1+ (1,0) [0E-008|1.00000000] "" ECM,ECM_Fuel,ADC,MRR,LRCR,RRCR,APA,FLL
SG_ VCU_Vehicle_Run_Mode_S : 20|2@1+ (1,0) [0E-008|3.00000000] "" Left_BCM,Right_BCM,Rear_BCM,LTE4G,ECM,ECM_Fuel,SRS,ADC,LRCR,RRCR,FCR,MSR_DRV
SG_ VCU_Vehicle_Run_Mode_S2 : 22|2@1+ (1,0) [0E-008|3.00000000] "" Left_BCM,Right_BCM,Rear_BCM,LTE4G,ECM,ECM_Fuel,SRS,ADC,LRCR,RRCR,FCR,MSR_DRV
SG_ VCU_Goal_Gear_S : 24|4@1+ (1,0) [0E-008|15.00000000] "" Left_BCM,Right_BCM,Rear_BCM,SEC,HFRM,LTE4G,CS,RRSE,IRM,PM25,SECUP,SRS,ADC,LRCR,RRCR,FCR,APA,FLL,FLR,MSR_DRV
SG_ Ins_disp_veh_work_mod : 28|2@1+ (1,0) [0E-008|3.00000000] "" Left_BCM,Right_BCM,Rear_BCM,SEC,HFRM,LTE4G,ECM,ECM_Fuel,SRS,ADC,LRCR,RRCR,FCR,APA,FLL,FLR,MSR_DRV
SG_ Tar_road_mod : 37|3@1+ (1,0) [0E-008|7.00000000] "" Left_BCM,Right_BCM,Rear_BCM,LTE4G,ECM,ECM_Fuel,SRS,ADC,LRCR,RRCR,FCR,MSR_DRV
SG_ Act_road_mod : 45|3@1+ (1,0) [0E-008|7.00000000] "" Left_BCM,Right_BCM,Rear_BCM,LTE4G,ECM,ECM_Fuel,SRS,ADC,LRCR,RRCR,FCR,MSR_DRV
SG_ Counter_342_S : 52|4@1+ (1,0) [0E-008|15.00000000] "" Left_BCM,Right_BCM,Rear_BCM,ISG,BSG,TCU_Fuel,SRS,ADC,LRCR,RRCR,FCR,APA,FLL,FLR,MSR_DRV
SG_ Checksum_342_S : 56|8@1+ (1,0) [0E-008|255.00000000] "" Left_BCM,Right_BCM,Rear_BCM,LTE4G,ISG,BSG,TCU_Fuel,SRS,ADC,LRCR,RRCR,FCR,APA,FLL,FLR,MSR_DRV
BO_ 944 SWS_0x3B0: 8 SWS
SG_ SWS_Dist_Set_S : 0|3@1+ (1,0) [0E-008|7.00000000] "" ADC
SG_ SWS_Speed_Set_S : 3|3@1+ (1,0) [0E-008|7.00000000] "" ADC
SG_ Dipilot_Switch_Signal_S : 6|2@1+ (1,0) [0E-008|3.00000000] "" ADC
SG_ SWS_Cruise_Or_Speed_Limit_Mode_S : 8|2@1+ (1,0) [0E-008|3.00000000] "" ADC
SG_ SWS_Reset_Signal_S : 10|2@1+ (1,0) [0E-008|3.00000000] "" ADC
SG_ SWS_Cruis_Swch_Fault_Stat_flg_S : 12|2@1+ (1,0) [0E-008|3.00000000] "" ADC
SG_ SWS_Set_Signal_S : 14|1@1+ (1,0) [0E-008|1.00000000] "" ADC
SG_ SWS_Dist_Switch_Signal_Down_S : 15|1@1+ (1,0) [0E-008|1.00000000] "" ADC
SG_ SWS_Dist_Switch_Signal_Up_S : 16|1@1+ (1,0) [0E-008|1.00000000] "" ADC
SG_ Cruise_Switch_Operation_Mode_S : 18|1@1+ (1,0) [0E-008|1.00000000] "" ADC
SG_ ACC_Switch_Signal_S : 19|1@1+ (1,0) [0E-008|1.00000000] "" ADC
SG_ HOD_System_Status_S : 20|3@1+ (1,0) [0E-008|7.00000000] "" ADC
SG_ Driver_Grip_S : 24|3@1+ (1,0) [0E-008|7.00000000] "" ADC
SG_ Driver_Grip_Area_S : 27|3@1+ (1,0) [0E-008|7.00000000] "" ADC
SG_ Driver_SingleHands_State_S : 32|3@1+ (1,0) [0E-008|7.00000000] "" ADC
SG_ Left_Paddle_For_Advanced_Driving_Functions_S : 35|2@1+ (1,0) [0E-008|3.00000000] "" ADC
SG_ Right_Paddle_For_Advanced_Driving_Functions_S : 37|2@1+ (1,0) [0E-008|3.00000000] "" ADC
SG_ APA : 39|1@1+ (1,0) [0E-008|1.00000000] "" ADC
SG_ Road_Speed_Limit_Seting_S : 42|1@1+ (1,0) [0E-008|1.00000000] "" ADC
SG_ Vehicle_Distance_button_Flag_S : 43|1@1+ (1,0) [0E-008|1.00000000] "" ADC
SG_ Counter_3B0_S : 52|4@1+ (1,0) [0E-008|15.00000000] "" ADC
SG_ Checksum_3B0_S : 56|8@1+ (1,0) [0E-008|255.00000000] "" ADC
BO_ 1646 MRR_0x66E: 32 MRR
SG_ Checksum_62F_S : 0|16@1+ (1,0) [0E-008|65535.00000000] "" ADC
SG_ Counter_62F_S : 16|8@1+ (1,0) [0E-008|255.00000000] "" ADC
SG_ ARS_OD_TimeStampGlobSec : 24|32@1+ (1,0) [0E-008|4294967295.00000000] "s" ADC
SG_ ARS_OD_TimeStampGlobNanoSec : 56|32@1+ (1,0) [0E-008|4294967295.00000000] "ns" ADC
SG_ ARS_OD_TimeStampLocal : 88|32@1+ (1,0) [0E-008|4294967295.00000000] "ns" ADC
SG_ ARS_OD_Latency : 120|11@1+ (0.1000000000000000055511151231257827021181583404541015625,30) [30.00000000|234.70000000] "ms" ADC
SG_ ARS_OD_MeasCounter : 131|16@1+ (1,0) [0E-008|65535.00000000] "unitless" ADC
SG_ ARS_OD_CycleCounter : 147|16@1+ (1,0) [0E-008|65535.00000000] "unitless" ADC
SG_ ARS_OD_NumOfObjects : 163|6@1+ (1,0) [0E-008|63.00000000] "unitless" ADC
SG_ ARS_OD_TaskValidFlag : 169|1@1+ (1,0) [0E-008|1.00000000] "unitless" ADC
SG_ ARS_OD_ExtendedCycleFlag : 170|1@1+ (1,0) [0E-008|1.00000000] "unitless" ADC
SG_ ARS_OD_EgoVelocity : 171|11@1+ (0.125,-128) [-128.00000000|127.87500000] "m/s" ADC
SG_ ARS_OD_EgoVelocityStd : 182|7@1+ (0.1000000000000000055511151231257827021181583404541015625,0) [0E-008|12.70000000] "m/s" ADC
SG_ ARS_OD_EgoAcceleration : 189|9@1+ (0.125,-31.875) [-31.87500000|32.00000000] "m/s^2" ADC
SG_ ARS_OD_EgoYawRate : 198|10@1+ (0.001000000000000000020816681711721685132943093776702880859375,-0.51100000000000000976996261670137755572795867919921875) [-0.51100000|0.51200000] "rad/s" ADC
SG_ ARS_OD_EgoYawRateStd : 208|10@1+ (0.000100000000000000004792173602385929598312941379845142364501953125,0) [0E-008|0.10230000] "rad/s" ADC
SG_ ARS_OD_EgoCurvature : 218|8@1+ (0.001000000000000000020816681711721685132943093776702880859375,0) [0E-008|0.25500000] "1/m" ADC
SG_ ARS_OD_TimesynSts : 232|8@1+ (1,0) [0E-008|255.00000000] "" ADC
SG_ MRR_SYNC_offset : 240|10@1+ (1,0) [0E-008|1000.00000000] "ms" ADC
BO_ 1600 MRR_0x640: 64 MRR
SG_ Checksum_601_S : 0|16@1+ (1,0) [0E-008|65535.00000000] "" ADC
SG_ Counter_601_S : 16|8@1+ (1,0) [0E-008|255.00000000] "" ADC
SG_ ARS_RDI_Range_Clu_000 : 24|12@1+ (0.0625,0) [0E-008|255.93750000] "m" ADC
SG_ ARS_RDI_VradRel_Clu_000 : 36|11@1+ (0.1000000000000000055511151231257827021181583404541015625,-120) [-120.00000000|84.70000000] "m/s" ADC
SG_ ARS_RDI_AzimuthAng_Clu_000 : 47|10@1+ (0.00200000000000000004163336342344337026588618755340576171875,-1.0220000000000000195399252334027551114559173583984375) [-1.02200000|1.02400000] "rad" ADC
SG_ ARS_RDI_ElevationAng_Clu_000 : 57|7@1+ (0.005000000000000000104083408558608425664715468883514404296875,-0.315000000000000002220446049250313080847263336181640625) [-0.31500000|0.32000000] "rad" ADC
SG_ ARS_RDI_RCS_Clu_000 : 64|9@1+ (0.200000000000000011102230246251565404236316680908203125,-51.10000000000000142108547152020037174224853515625) [-51.10000000|51.10000000] "dBsm" ADC
SG_ ARS_RDI_SNR_Clu_000 : 73|7@1+ (0.5,0) [0E-008|63.50000000] "dB" ADC
SG_ ARS_RDI_DynProp_Clu_000 : 80|2@1+ (1,0) [0E-008|3.00000000] "unitless" ADC
SG_ ARS_RDI_Quality_Clu_000 : 82|2@1+ (1,0) [0E-008|3.00000000] "unitless" ADC
SG_ ARS_RDI_Range_Clu_001 : 84|12@1+ (0.0625,0) [0E-008|255.93750000] "m" ADC
SG_ ARS_RDI_VradRel_Clu_001 : 96|11@1+ (0.1000000000000000055511151231257827021181583404541015625,-120) [-120.00000000|84.70000000] "m/s" ADC
SG_ ARS_RDI_AzimuthAng_Clu_001 : 107|10@1+ (0.00200000000000000004163336342344337026588618755340576171875,-1.0220000000000000195399252334027551114559173583984375) [-1.02200000|1.02400000] "rad" ADC
SG_ ARS_RDI_ElevationAng_Clu_001 : 117|7@1+ (0.005000000000000000104083408558608425664715468883514404296875,-0.315000000000000002220446049250313080847263336181640625) [-0.31500000|0.32000000] "rad" ADC
SG_ ARS_RDI_RCS_Clu_001 : 124|9@1+ (0.200000000000000011102230246251565404236316680908203125,-51.10000000000000142108547152020037174224853515625) [-51.10000000|51.10000000] "dBsm" ADC
SG_ ARS_RDI_SNR_Clu_001 : 133|7@1+ (0.5,0) [0E-008|63.50000000] "dB" ADC
SG_ ARS_RDI_DynProp_Clu_001 : 140|2@1+ (1,0) [0E-008|3.00000000] "unitless" ADC
SG_ ARS_RDI_Quality_Clu_001 : 142|2@1+ (1,0) [0E-008|3.00000000] "unitless" ADC
SG_ ARS_RDI_Range_Clu_002 : 144|12@1+ (0.0625,0) [0E-008|255.93750000] "m" ADC
SG_ ARS_RDI_VradRel_Clu_002 : 156|11@1+ (0.1000000000000000055511151231257827021181583404541015625,-120) [-120.00000000|84.70000000] "m/s" ADC
SG_ ARS_RDI_AzimuthAng_Clu_002 : 167|10@1+ (0.00200000000000000004163336342344337026588618755340576171875,-1.0220000000000000195399252334027551114559173583984375) [-1.02200000|1.02400000] "rad" ADC
SG_ ARS_RDI_ElevationAng_Clu_002 : 177|7@1+ (0.005000000000000000104083408558608425664715468883514404296875,-0.315000000000000002220446049250313080847263336181640625) [-0.31500000|0.32000000] "rad" ADC
SG_ ARS_RDI_RCS_Clu_002 : 184|9@1+ (0.200000000000000011102230246251565404236316680908203125,-51.10000000000000142108547152020037174224853515625) [-51.10000000|51.10000000] "dBsm" ADC
SG_ ARS_RDI_SNR_Clu_002 : 193|7@1+ (0.5,0) [0E-008|63.50000000] "dB" ADC
SG_ ARS_RDI_DynProp_Clu_002 : 200|2@1+ (1,0) [0E-008|3.00000000] "unitless" ADC
SG_ ARS_RDI_Quality_Clu_002 : 202|2@1+ (1,0) [0E-008|3.00000000] "unitless" ADC
SG_ ARS_RDI_Range_Clu_003 : 204|12@1+ (0.0625,0) [0E-008|255.93750000] "m" ADC
SG_ ARS_RDI_VradRel_Clu_003 : 216|11@1+ (0.1000000000000000055511151231257827021181583404541015625,-120) [-120.00000000|84.70000000] "m/s" ADC
SG_ ARS_RDI_AzimuthAng_Clu_003 : 227|10@1+ (0.00200000000000000004163336342344337026588618755340576171875,-1.0220000000000000195399252334027551114559173583984375) [-1.02200000|1.02400000] "rad" ADC
SG_ ARS_RDI_ElevationAng_Clu_003 : 237|7@1+ (0.005000000000000000104083408558608425664715468883514404296875,-0.315000000000000002220446049250313080847263336181640625) [-0.31500000|0.32000000] "rad" ADC
SG_ ARS_RDI_RCS_Clu_003 : 244|9@1+ (0.200000000000000011102230246251565404236316680908203125,-51.10000000000000142108547152020037174224853515625) [-51.10000000|51.10000000] "dBsm" ADC
SG_ ARS_RDI_SNR_Clu_003 : 253|7@1+ (0.5,0) [0E-008|63.50000000] "dB" ADC
SG_ ARS_RDI_DynProp_Clu_003 : 260|2@1+ (1,0) [0E-008|3.00000000] "unitless" ADC
SG_ ARS_RDI_Quality_Clu_003 : 262|2@1+ (1,0) [0E-008|3.00000000] "unitless" ADC
SG_ ARS_RDI_Range_Clu_004 : 264|12@1+ (0.0625,0) [0E-008|255.93750000] "m" ADC
SG_ ARS_RDI_VradRel_Clu_004 : 276|11@1+ (0.1000000000000000055511151231257827021181583404541015625,-120) [-120.00000000|84.70000000] "m/s" ADC
SG_ ARS_RDI_AzimuthAng_Clu_004 : 287|10@1+ (0.00200000000000000004163336342344337026588618755340576171875,-1.0220000000000000195399252334027551114559173583984375) [-1.02200000|1.02400000] "rad" ADC
SG_ ARS_RDI_ElevationAng_Clu_004 : 297|7@1+ (0.005000000000000000104083408558608425664715468883514404296875,-0.315000000000000002220446049250313080847263336181640625) [-0.31500000|0.32000000] "rad" ADC
SG_ ARS_RDI_RCS_Clu_004 : 304|9@1+ (0.200000000000000011102230246251565404236316680908203125,-51.10000000000000142108547152020037174224853515625) [-51.10000000|51.10000000] "dBsm" ADC
SG_ ARS_RDI_SNR_Clu_004 : 313|7@1+ (0.5,0) [0E-008|63.50000000] "dB" ADC
SG_ ARS_RDI_DynProp_Clu_004 : 320|2@1+ (1,0) [0E-008|3.00000000] "unitless" ADC
SG_ ARS_RDI_Quality_Clu_004 : 322|2@1+ (1,0) [0E-008|3.00000000] "unitless" ADC
SG_ ARS_RDI_Range_Clu_005 : 324|12@1+ (0.0625,0) [0E-008|255.93750000] "m" ADC
SG_ ARS_RDI_VradRel_Clu_005 : 336|11@1+ (0.1000000000000000055511151231257827021181583404541015625,-120) [-120.00000000|84.70000000] "m/s" ADC
SG_ ARS_RDI_AzimuthAng_Clu_005 : 347|10@1+ (0.00200000000000000004163336342344337026588618755340576171875,-1.0220000000000000195399252334027551114559173583984375) [-1.02200000|1.02400000] "rad" ADC
SG_ ARS_RDI_ElevationAng_Clu_005 : 357|7@1+ (0.005000000000000000104083408558608425664715468883514404296875,-0.315000000000000002220446049250313080847263336181640625) [-0.31500000|0.32000000] "rad" ADC
SG_ ARS_RDI_RCS_Clu_005 : 364|9@1+ (0.200000000000000011102230246251565404236316680908203125,-51.10000000000000142108547152020037174224853515625) [-51.10000000|51.10000000] "dBsm" ADC
SG_ ARS_RDI_SNR_Clu_005 : 373|7@1+ (0.5,0) [0E-008|63.50000000] "dB" ADC
SG_ ARS_RDI_DynProp_Clu_005 : 380|2@1+ (1,0) [0E-008|3.00000000] "unitless" ADC
SG_ ARS_RDI_Quality_Clu_005 : 382|2@1+ (1,0) [0E-008|3.00000000] "unitless" ADC
SG_ ARS_RDI_Range_Clu_006 : 384|12@1+ (0.0625,0) [0E-008|255.93750000] "m" ADC
SG_ ARS_RDI_VradRel_Clu_006 : 396|11@1+ (0.1000000000000000055511151231257827021181583404541015625,-120) [-120.00000000|84.70000000] "m/s" ADC
SG_ ARS_RDI_AzimuthAng_Clu_006 : 407|10@1+ (0.00200000000000000004163336342344337026588618755340576171875,-1.0220000000000000195399252334027551114559173583984375) [-1.02200000|1.02400000] "rad" ADC
SG_ ARS_RDI_ElevationAng_Clu_006 : 417|7@1+ (0.005000000000000000104083408558608425664715468883514404296875,-0.315000000000000002220446049250313080847263336181640625) [-0.31500000|0.32000000] "rad" ADC
SG_ ARS_RDI_RCS_Clu_006 : 424|9@1+ (0.200000000000000011102230246251565404236316680908203125,-51.10000000000000142108547152020037174224853515625) [-51.10000000|51.10000000] "dBsm" ADC
SG_ ARS_RDI_SNR_Clu_006 : 433|7@1+ (0.5,0) [0E-008|63.50000000] "dB" ADC
SG_ ARS_RDI_DynProp_Clu_006 : 440|2@1+ (1,0) [0E-008|3.00000000] "unitless" ADC
SG_ ARS_RDI_Quality_Clu_006 : 442|2@1+ (1,0) [0E-008|3.00000000] "unitless" ADC
SG_ ARS_RDI_Range_Clu_007 : 444|12@1+ (0.0625,0) [0E-008|255.93750000] "m" ADC
SG_ ARS_RDI_VradRel_Clu_007 : 456|11@1+ (0.1000000000000000055511151231257827021181583404541015625,-120) [-120.00000000|84.70000000] "m/s" ADC
SG_ ARS_RDI_AzimuthAng_Clu_007 : 467|10@1+ (0.00200000000000000004163336342344337026588618755340576171875,-1.0220000000000000195399252334027551114559173583984375) [-1.02200000|1.02400000] "rad" ADC
SG_ ARS_RDI_ElevationAng_Clu_007 : 477|7@1+ (0.005000000000000000104083408558608425664715468883514404296875,-0.315000000000000002220446049250313080847263336181640625) [-0.31500000|0.32000000] "rad" ADC
SG_ ARS_RDI_RCS_Clu_007 : 484|9@1+ (0.200000000000000011102230246251565404236316680908203125,-51.10000000000000142108547152020037174224853515625) [-51.10000000|51.10000000] "dBsm" ADC
SG_ ARS_RDI_SNR_Clu_007 : 493|7@1+ (0.5,0) [0E-008|63.50000000] "dB" ADC
SG_ ARS_RDI_DynProp_Clu_007 : 500|2@1+ (1,0) [0E-008|3.00000000] "unitless" ADC
SG_ ARS_RDI_Quality_Clu_007 : 502|2@1+ (1,0) [0E-008|3.00000000] "unitless" ADC
BO_ 1601 MRR_0x641: 64 MRR
SG_ Checksum_602_S : 0|16@1+ (1,0) [0E-008|65535.00000000] "" ADC
SG_ Counter_602_S : 16|8@1+ (1,0) [0E-008|255.00000000] "" ADC
SG_ ARS_RDI_Range_Clu_008 : 24|12@1+ (0.0625,0) [0E-008|255.93750000] "m" ADC
SG_ ARS_RDI_VradRel_Clu_008 : 36|11@1+ (0.1000000000000000055511151231257827021181583404541015625,-120) [-120.00000000|84.70000000] "m/s" ADC
SG_ ARS_RDI_AzimuthAng_Clu_008 : 47|10@1+ (0.00200000000000000004163336342344337026588618755340576171875,-1.0220000000000000195399252334027551114559173583984375) [-1.02200000|1.02400000] "rad" ADC
SG_ ARS_RDI_ElevationAng_Clu_008 : 57|7@1+ (0.005000000000000000104083408558608425664715468883514404296875,-0.315000000000000002220446049250313080847263336181640625) [-0.31500000|0.32000000] "rad" ADC
SG_ ARS_RDI_RCS_Clu_008 : 64|9@1+ (0.200000000000000011102230246251565404236316680908203125,-51.10000000000000142108547152020037174224853515625) [-51.10000000|51.10000000] "dBsm" ADC
SG_ ARS_RDI_SNR_Clu_008 : 73|7@1+ (0.5,0) [0E-008|63.50000000] "dB" ADC
SG_ ARS_RDI_DynProp_Clu_008 : 80|2@1+ (1,0) [0E-008|3.00000000] "unitless" ADC
SG_ ARS_RDI_Quality_Clu_008 : 82|2@1+ (1,0) [0E-008|3.00000000] "unitless" ADC
SG_ ARS_RDI_Range_Clu_009 : 84|12@1+ (0.0625,0) [0E-008|255.93750000] "m" ADC
SG_ ARS_RDI_VradRel_Clu_009 : 96|11@1+ (0.1000000000000000055511151231257827021181583404541015625,-120) [-120.00000000|84.70000000] "m/s" ADC
SG_ ARS_RDI_AzimuthAng_Clu_009 : 107|10@1+ (0.00200000000000000004163336342344337026588618755340576171875,-1.0220000000000000195399252334027551114559173583984375) [-1.02200000|1.02400000] "rad" ADC
SG_ ARS_RDI_ElevationAng_Clu_009 : 117|7@1+ (0.005000000000000000104083408558608425664715468883514404296875,-0.315000000000000002220446049250313080847263336181640625) [-0.31500000|0.32000000] "rad" ADC
SG_ ARS_RDI_RCS_Clu_009 : 124|9@1+ (0.200000000000000011102230246251565404236316680908203125,-51.10000000000000142108547152020037174224853515625) [-51.10000000|51.10000000] "dBsm" ADC
SG_ ARS_RDI_SNR_Clu_009 : 133|7@1+ (0.5,0) [0E-008|63.50000000] "dB" ADC
SG_ ARS_RDI_DynProp_Clu_009 : 140|2@1+ (1,0) [0E-008|3.00000000] "unitless" ADC
SG_ ARS_RDI_Quality_Clu_009 : 142|2@1+ (1,0) [0E-008|3.00000000] "unitless" ADC
SG_ ARS_RDI_Range_Clu_010 : 144|12@1+ (0.0625,0) [0E-008|255.93750000] "m" ADC
SG_ ARS_RDI_VradRel_Clu_010 : 156|11@1+ (0.1000000000000000055511151231257827021181583404541015625,-120) [-120.00000000|84.70000000] "m/s" ADC
SG_ ARS_RDI_AzimuthAng_Clu_010 : 167|10@1+ (0.00200000000000000004163336342344337026588618755340576171875,-1.0220000000000000195399252334027551114559173583984375) [-1.02200000|1.02400000] "rad" ADC
SG_ ARS_RDI_ElevationAng_Clu_010 : 177|7@1+ (0.005000000000000000104083408558608425664715468883514404296875,-0.315000000000000002220446049250313080847263336181640625) [-0.31500000|0.32000000] "rad" ADC
SG_ ARS_RDI_RCS_Clu_010 : 184|9@1+ (0.200000000000000011102230246251565404236316680908203125,-51.10000000000000142108547152020037174224853515625) [-51.10000000|51.10000000] "dBsm" ADC
SG_ ARS_RDI_SNR_Clu_010 : 193|7@1+ (0.5,0) [0E-008|63.50000000] "dB" ADC
SG_ ARS_RDI_DynProp_Clu_010 : 200|2@1+ (1,0) [0E-008|3.00000000] "unitless" ADC
SG_ ARS_RDI_Quality_Clu_010 : 202|2@1+ (1,0) [0E-008|3.00000000] "unitless" ADC
SG_ ARS_RDI_Range_Clu_011 : 204|12@1+ (0.0625,0) [0E-008|255.93750000] "m" ADC
SG_ ARS_RDI_VradRel_Clu_011 : 216|11@1+ (0.1000000000000000055511151231257827021181583404541015625,-120) [-120.00000000|84.70000000] "m/s" ADC
SG_ ARS_RDI_AzimuthAng_Clu_011 : 227|10@1+ (0.00200000000000000004163336342344337026588618755340576171875,-1.0220000000000000195399252334027551114559173583984375) [-1.02200000|1.02400000] "rad" ADC
SG_ ARS_RDI_ElevationAng_Clu_011 : 237|7@1+ (0.005000000000000000104083408558608425664715468883514404296875,-0.315000000000000002220446049250313080847263336181640625) [-0.31500000|0.32000000] "rad" ADC
SG_ ARS_RDI_RCS_Clu_011 : 244|9@1+ (0.200000000000000011102230246251565404236316680908203125,-51.10000000000000142108547152020037174224853515625) [-51.10000000|51.10000000] "dBsm" ADC
SG_ ARS_RDI_SNR_Clu_011 : 253|7@1+ (0.5,0) [0E-008|63.50000000] "dB" ADC
SG_ ARS_RDI_DynProp_Clu_011 : 260|2@1+ (1,0) [0E-008|3.00000000] "unitless" ADC
SG_ ARS_RDI_Quality_Clu_011 : 262|2@1+ (1,0) [0E-008|3.00000000] "unitless" ADC
SG_ ARS_RDI_Range_Clu_012 : 264|12@1+ (0.0625,0) [0E-008|255.93750000] "m" ADC
SG_ ARS_RDI_VradRel_Clu_012 : 276|11@1+ (0.1000000000000000055511151231257827021181583404541015625,-120) [-120.00000000|84.70000000] "m/s" ADC
SG_ ARS_RDI_AzimuthAng_Clu_012 : 287|10@1+ (0.00200000000000000004163336342344337026588618755340576171875,-1.0220000000000000195399252334027551114559173583984375) [-1.02200000|1.02400000] "rad" ADC
SG_ ARS_RDI_ElevationAng_Clu_012 : 297|7@1+ (0.005000000000000000104083408558608425664715468883514404296875,-0.315000000000000002220446049250313080847263336181640625) [-0.31500000|0.32000000] "rad" ADC
SG_ ARS_RDI_RCS_Clu_012 : 304|9@1+ (0.200000000000000011102230246251565404236316680908203125,-51.10000000000000142108547152020037174224853515625) [-51.10000000|51.10000000] "dBsm" ADC
SG_ ARS_RDI_SNR_Clu_012 : 313|7@1+ (0.5,0) [0E-008|63.50000000] "dB" ADC
SG_ ARS_RDI_DynProp_Clu_012 : 320|2@1+ (1,0) [0E-008|3.00000000] "unitless" ADC
SG_ ARS_RDI_Quality_Clu_012 : 322|2@1+ (1,0) [0E-008|3.00000000] "unitless" ADC
SG_ ARS_RDI_Range_Clu_013 : 324|12@1+ (0.0625,0) [0E-008|255.93750000] "m" ADC
SG_ ARS_RDI_VradRel_Clu_013 : 336|11@1+ (0.1000000000000000055511151231257827021181583404541015625,-120) [-120.00000000|84.70000000] "m/s" ADC
SG_ ARS_RDI_AzimuthAng_Clu_013 : 347|10@1+ (0.00200000000000000004163336342344337026588618755340576171875,-1.0220000000000000195399252334027551114559173583984375) [-1.02200000|1.02400000] "rad" ADC
SG_ ARS_RDI_ElevationAng_Clu_013 : 357|7@1+ (0.005000000000000000104083408558608425664715468883514404296875,-0.315000000000000002220446049250313080847263336181640625) [-0.31500000|0.32000000] "rad" ADC
SG_ ARS_RDI_RCS_Clu_013 : 364|9@1+ (0.200000000000000011102230246251565404236316680908203125,-51.10000000000000142108547152020037174224853515625) [-51.10000000|51.10000000] "dBsm" ADC
SG_ ARS_RDI_SNR_Clu_013 : 373|7@1+ (0.5,0) [0E-008|63.50000000] "dB" ADC
SG_ ARS_RDI_DynProp_Clu_013 : 380|2@1+ (1,0) [0E-008|3.00000000] "unitless" ADC
SG_ ARS_RDI_Quality_Clu_013 : 382|2@1+ (1,0) [0E-008|3.00000000] "unitless" ADC
SG_ ARS_RDI_Range_Clu_014 : 384|12@1+ (0.0625,0) [0E-008|255.93750000] "m" ADC
SG_ ARS_RDI_VradRel_Clu_014 : 396|11@1+ (0.1000000000000000055511151231257827021181583404541015625,-120) [-120.00000000|84.70000000] "m/s" ADC
SG_ ARS_RDI_AzimuthAng_Clu_014 : 407|10@1+ (0.00200000000000000004163336342344337026588618755340576171875,-1.0220000000000000195399252334027551114559173583984375) [-1.02200000|1.02400000] "rad" ADC
SG_ ARS_RDI_ElevationAng_Clu_014 : 417|7@1+ (0.005000000000000000104083408558608425664715468883514404296875,-0.315000000000000002220446049250313080847263336181640625) [-0.31500000|0.32000000] "rad" ADC
SG_ ARS_RDI_RCS_Clu_014 : 424|9@1+ (0.200000000000000011102230246251565404236316680908203125,-51.10000000000000142108547152020037174224853515625) [-51.10000000|51.10000000] "dBsm" ADC
SG_ ARS_RDI_SNR_Clu_014 : 433|7@1+ (0.5,0) [0E-008|63.50000000] "dB" ADC
SG_ ARS_RDI_DynProp_Clu_014 : 440|2@1+ (1,0) [0E-008|3.00000000] "unitless" ADC
SG_ ARS_RDI_Quality_Clu_014 : 442|2@1+ (1,0) [0E-008|3.00000000] "unitless" ADC
SG_ ARS_RDI_Range_Clu_015 : 444|12@1+ (0.0625,0) [0E-008|255.93750000] "m" ADC
SG_ ARS_RDI_VradRel_Clu_015 : 456|11@1+ (0.1000000000000000055511151231257827021181583404541015625,-120) [-120.00000000|84.70000000] "m/s" ADC
SG_ ARS_RDI_AzimuthAng_Clu_015 : 467|10@1+ (0.00200000000000000004163336342344337026588618755340576171875,-1.0220000000000000195399252334027551114559173583984375) [-1.02200000|1.02400000] "rad" ADC
SG_ ARS_RDI_ElevationAng_Clu_015 : 477|7@1+ (0.005000000000000000104083408558608425664715468883514404296875,-0.315000000000000002220446049250313080847263336181640625) [-0.31500000|0.32000000] "rad" ADC
SG_ ARS_RDI_RCS_Clu_015 : 484|9@1+ (0.200000000000000011102230246251565404236316680908203125,-51.10000000000000142108547152020037174224853515625) [-51.10000000|51.10000000] "dBsm" ADC
SG_ ARS_RDI_SNR_Clu_015 : 493|7@1+ (0.5,0) [0E-008|63.50000000] "dB" ADC
SG_ ARS_RDI_DynProp_Clu_015 : 500|2@1+ (1,0) [0E-008|3.00000000] "unitless" ADC
SG_ ARS_RDI_Quality_Clu_015 : 502|2@1+ (1,0) [0E-008|3.00000000] "unitless" ADC
BO_ 1602 MRR_0x642: 64 MRR
SG_ Checksum_603_S : 0|16@1+ (1,0) [0E-008|65535.00000000] "" ADC
SG_ Counter_603_S : 16|8@1+ (1,0) [0E-008|255.00000000] "" ADC
SG_ ARS_RDI_Range_Clu_016 : 24|12@1+ (0.0625,0) [0E-008|255.93750000] "m" ADC
SG_ ARS_RDI_VradRel_Clu_016 : 36|11@1+ (0.1000000000000000055511151231257827021181583404541015625,-120) [-120.00000000|84.70000000] "m/s" ADC
SG_ ARS_RDI_AzimuthAng_Clu_016 : 47|10@1+ (0.00200000000000000004163336342344337026588618755340576171875,-1.0220000000000000195399252334027551114559173583984375) [-1.02200000|1.02400000] "rad" ADC
SG_ ARS_RDI_ElevationAng_Clu_016 : 57|7@1+ (0.005000000000000000104083408558608425664715468883514404296875,-0.315000000000000002220446049250313080847263336181640625) [-0.31500000|0.32000000] "rad" ADC
SG_ ARS_RDI_RCS_Clu_016 : 64|9@1+ (0.200000000000000011102230246251565404236316680908203125,-51.10000000000000142108547152020037174224853515625) [-51.10000000|51.10000000] "dBsm" ADC
SG_ ARS_RDI_SNR_Clu_016 : 73|7@1+ (0.5,0) [0E-008|63.50000000] "dB" ADC
SG_ ARS_RDI_DynProp_Clu_016 : 80|2@1+ (1,0) [0E-008|3.00000000] "unitless" ADC
SG_ ARS_RDI_Quality_Clu_016 : 82|2@1+ (1,0) [0E-008|3.00000000] "unitless" ADC
SG_ ARS_RDI_Range_Clu_017 : 84|12@1+ (0.0625,0) [0E-008|255.93750000] "m" ADC
SG_ ARS_RDI_VradRel_Clu_017 : 96|11@1+ (0.1000000000000000055511151231257827021181583404541015625,-120) [-120.00000000|84.70000000] "m/s" ADC
SG_ ARS_RDI_AzimuthAng_Clu_017 : 107|10@1+ (0.00200000000000000004163336342344337026588618755340576171875,-1.0220000000000000195399252334027551114559173583984375) [-1.02200000|1.02400000] "rad" ADC
SG_ ARS_RDI_ElevationAng_Clu_017 : 117|7@1+ (0.005000000000000000104083408558608425664715468883514404296875,-0.315000000000000002220446049250313080847263336181640625) [-0.31500000|0.32000000] "rad" ADC
SG_ ARS_RDI_RCS_Clu_017 : 124|9@1+ (0.200000000000000011102230246251565404236316680908203125,-51.10000000000000142108547152020037174224853515625) [-51.10000000|51.10000000] "dBsm" ADC
SG_ ARS_RDI_SNR_Clu_017 : 133|7@1+ (0.5,0) [0E-008|63.50000000] "dB" ADC
SG_ ARS_RDI_DynProp_Clu_017 : 140|2@1+ (1,0) [0E-008|3.00000000] "unitless" ADC
SG_ ARS_RDI_Quality_Clu_017 : 142|2@1+ (1,0) [0E-008|3.00000000] "unitless" ADC
SG_ ARS_RDI_Range_Clu_018 : 144|12@1+ (0.0625,0) [0E-008|255.93750000] "m" ADC
SG_ ARS_RDI_VradRel_Clu_018 : 156|11@1+ (0.1000000000000000055511151231257827021181583404541015625,-120) [-120.00000000|84.70000000] "m/s" ADC
SG_ ARS_RDI_AzimuthAng_Clu_018 : 167|10@1+ (0.00200000000000000004163336342344337026588618755340576171875,-1.0220000000000000195399252334027551114559173583984375) [-1.02200000|1.02400000] "rad" ADC
SG_ ARS_RDI_ElevationAng_Clu_018 : 177|7@1+ (0.005000000000000000104083408558608425664715468883514404296875,-0.315000000000000002220446049250313080847263336181640625) [-0.31500000|0.32000000] "rad" ADC
SG_ ARS_RDI_RCS_Clu_018 : 184|9@1+ (0.200000000000000011102230246251565404236316680908203125,-51.10000000000000142108547152020037174224853515625) [-51.10000000|51.10000000] "dBsm" ADC
SG_ ARS_RDI_SNR_Clu_018 : 193|7@1+ (0.5,0) [0E-008|63.50000000] "dB" ADC
SG_ ARS_RDI_DynProp_Clu_018 : 200|2@1+ (1,0) [0E-008|3.00000000] "unitless" ADC
SG_ ARS_RDI_Quality_Clu_018 : 202|2@1+ (1,0) [0E-008|3.00000000] "unitless" ADC
SG_ ARS_RDI_Range_Clu_019 : 204|12@1+ (0.0625,0) [0E-008|255.93750000] "m" ADC
SG_ ARS_RDI_VradRel_Clu_019 : 216|11@1+ (0.1000000000000000055511151231257827021181583404541015625,-120) [-120.00000000|84.70000000] "m/s" ADC
SG_ ARS_RDI_AzimuthAng_Clu_019 : 227|10@1+ (0.00200000000000000004163336342344337026588618755340576171875,-1.0220000000000000195399252334027551114559173583984375) [-1.02200000|1.02400000] "rad" ADC
SG_ ARS_RDI_ElevationAng_Clu_019 : 237|7@1+ (0.005000000000000000104083408558608425664715468883514404296875,-0.315000000000000002220446049250313080847263336181640625) [-0.31500000|0.32000000] "rad" ADC
SG_ ARS_RDI_RCS_Clu_019 : 244|9@1+ (0.200000000000000011102230246251565404236316680908203125,-51.10000000000000142108547152020037174224853515625) [-51.10000000|51.10000000] "dBsm" ADC
SG_ ARS_RDI_SNR_Clu_019 : 253|7@1+ (0.5,0) [0E-008|63.50000000] "dB" ADC
SG_ ARS_RDI_DynProp_Clu_019 : 260|2@1+ (1,0) [0E-008|3.00000000] "unitless" ADC
SG_ ARS_RDI_Quality_Clu_019 : 262|2@1+ (1,0) [0E-008|3.00000000] "unitless" ADC
SG_ ARS_RDI_Range_Clu_020 : 264|12@1+ (0.0625,0) [0E-008|255.93750000] "m" ADC
SG_ ARS_RDI_VradRel_Clu_020 : 276|11@1+ (0.1000000000000000055511151231257827021181583404541015625,-120) [-120.00000000|84.70000000] "m/s" ADC
SG_ ARS_RDI_AzimuthAng_Clu_020 : 287|10@1+ (0.00200000000000000004163336342344337026588618755340576171875,-1.0220000000000000195399252334027551114559173583984375) [-1.02200000|1.02400000] "rad" ADC
SG_ ARS_RDI_ElevationAng_Clu_020 : 297|7@1+ (0.005000000000000000104083408558608425664715468883514404296875,-0.315000000000000002220446049250313080847263336181640625) [-0.31500000|0.32000000] "rad" ADC
SG_ ARS_RDI_RCS_Clu_020 : 304|9@1+ (0.200000000000000011102230246251565404236316680908203125,-51.10000000000000142108547152020037174224853515625) [-51.10000000|51.10000000] "dBsm" ADC
SG_ ARS_RDI_SNR_Clu_020 : 313|7@1+ (0.5,0) [0E-008|63.50000000] "dB" ADC
SG_ ARS_RDI_DynProp_Clu_020 : 320|2@1+ (1,0) [0E-008|3.00000000] "unitless" ADC
SG_ ARS_RDI_Quality_Clu_020 : 322|2@1+ (1,0) [0E-008|3.00000000] "unitless" ADC
SG_ ARS_RDI_Range_Clu_021 : 324|12@1+ (0.0625,0) [0E-008|255.93750000] "m" ADC
SG_ ARS_RDI_VradRel_Clu_021 : 336|11@1+ (0.1000000000000000055511151231257827021181583404541015625,-120) [-120.00000000|84.70000000] "m/s" ADC
SG_ ARS_RDI_AzimuthAng_Clu_021 : 347|10@1+ (0.00200000000000000004163336342344337026588618755340576171875,-1.0220000000000000195399252334027551114559173583984375) [-1.02200000|1.02400000] "rad" ADC
SG_ ARS_RDI_ElevationAng_Clu_021 : 357|7@1+ (0.005000000000000000104083408558608425664715468883514404296875,-0.315000000000000002220446049250313080847263336181640625) [-0.31500000|0.32000000] "rad" ADC
SG_ ARS_RDI_RCS_Clu_021 : 364|9@1+ (0.200000000000000011102230246251565404236316680908203125,-51.10000000000000142108547152020037174224853515625) [-51.10000000|51.10000000] "dBsm" ADC
SG_ ARS_RDI_SNR_Clu_021 : 373|7@1+ (0.5,0) [0E-008|63.50000000] "dB" ADC
SG_ ARS_RDI_DynProp_Clu_021 : 380|2@1+ (1,0) [0E-008|3.00000000] "unitless" ADC
SG_ ARS_RDI_Quality_Clu_021 : 382|2@1+ (1,0) [0E-008|3.00000000] "unitless" ADC
SG_ ARS_RDI_Range_Clu_022 : 384|12@1+ (0.0625,0) [0E-008|255.93750000] "m" ADC
SG_ ARS_RDI_VradRel_Clu_022 : 396|11@1+ (0.1000000000000000055511151231257827021181583404541015625,-120) [-120.00000000|84.70000000] "m/s" ADC
SG_ ARS_RDI_AzimuthAng_Clu_022 : 407|10@1+ (0.00200000000000000004163336342344337026588618755340576171875,-1.0220000000000000195399252334027551114559173583984375) [-1.02200000|1.02400000] "rad" ADC
SG_ ARS_RDI_ElevationAng_Clu_022 : 417|7@1+ (0.005000000000000000104083408558608425664715468883514404296875,-0.315000000000000002220446049250313080847263336181640625) [-0.31500000|0.32000000] "rad" ADC
SG_ ARS_RDI_RCS_Clu_022 : 424|9@1+ (0.200000000000000011102230246251565404236316680908203125,-51.10000000000000142108547152020037174224853515625) [-51.10000000|51.10000000] "dBsm" ADC
SG_ ARS_RDI_SNR_Clu_022 : 433|7@1+ (0.5,0) [0E-008|63.50000000] "dB" ADC
SG_ ARS_RDI_DynProp_Clu_022 : 440|2@1+ (1,0) [0E-008|3.00000000] "unitless" ADC
SG_ ARS_RDI_Quality_Clu_022 : 442|2@1+ (1,0) [0E-008|3.00000000] "unitless" ADC
SG_ ARS_RDI_Range_Clu_023 : 444|12@1+ (0.0625,0) [0E-008|255.93750000] "m" ADC
SG_ ARS_RDI_VradRel_Clu_023 : 456|11@1+ (0.1000000000000000055511151231257827021181583404541015625,-120) [-120.00000000|84.70000000] "m/s" ADC
SG_ ARS_RDI_AzimuthAng_Clu_023 : 467|10@1+ (0.00200000000000000004163336342344337026588618755340576171875,-1.0220000000000000195399252334027551114559173583984375) [-1.02200000|1.02400000] "rad" ADC
SG_ ARS_RDI_ElevationAng_Clu_023 : 477|7@1+ (0.005000000000000000104083408558608425664715468883514404296875,-0.315000000000000002220446049250313080847263336181640625) [-0.31500000|0.32000000] "rad" ADC
SG_ ARS_RDI_RCS_Clu_023 : 484|9@1+ (0.200000000000000011102230246251565404236316680908203125,-51.10000000000000142108547152020037174224853515625) [-51.10000000|51.10000000] "dBsm" ADC
SG_ ARS_RDI_SNR_Clu_023 : 493|7@1+ (0.5,0) [0E-008|63.50000000] "dB" ADC
SG_ ARS_RDI_DynProp_Clu_023 : 500|2@1+ (1,0) [0E-008|3.00000000] "unitless" ADC
SG_ ARS_RDI_Quality_Clu_023 : 502|2@1+ (1,0) [0E-008|3.00000000] "unitless" ADC
BO_ 1603 MRR_0x643: 64 MRR
SG_ Checksum_604_S : 0|16@1+ (1,0) [0E-008|65535.00000000] "" ADC
SG_ Counter_604_S : 16|8@1+ (1,0) [0E-008|255.00000000] "" ADC
SG_ ARS_RDI_Range_Clu_024 : 24|12@1+ (0.0625,0) [0E-008|255.93750000] "m" ADC
SG_ ARS_RDI_VradRel_Clu_024 : 36|11@1+ (0.1000000000000000055511151231257827021181583404541015625,-120) [-120.00000000|84.70000000] "m/s" ADC
SG_ ARS_RDI_AzimuthAng_Clu_024 : 47|10@1+ (0.00200000000000000004163336342344337026588618755340576171875,-1.0220000000000000195399252334027551114559173583984375) [-1.02200000|1.02400000] "rad" ADC
SG_ ARS_RDI_ElevationAng_Clu_024 : 57|7@1+ (0.005000000000000000104083408558608425664715468883514404296875,-0.315000000000000002220446049250313080847263336181640625) [-0.31500000|0.32000000] "rad" ADC
SG_ ARS_RDI_RCS_Clu_024 : 64|9@1+ (0.200000000000000011102230246251565404236316680908203125,-51.10000000000000142108547152020037174224853515625) [-51.10000000|51.10000000] "dBsm" ADC
SG_ ARS_RDI_SNR_Clu_024 : 73|7@1+ (0.5,0) [0E-008|63.50000000] "dB" ADC
SG_ ARS_RDI_DynProp_Clu_024 : 80|2@1+ (1,0) [0E-008|3.00000000] "unitless" ADC
SG_ ARS_RDI_Quality_Clu_024 : 82|2@1+ (1,0) [0E-008|3.00000000] "unitless" ADC
SG_ ARS_RDI_Range_Clu_025 : 84|12@1+ (0.0625,0) [0E-008|255.93750000] "m" ADC
SG_ ARS_RDI_VradRel_Clu_025 : 96|11@1+ (0.1000000000000000055511151231257827021181583404541015625,-120) [-120.00000000|84.70000000] "m/s" ADC
SG_ ARS_RDI_AzimuthAng_Clu_025 : 107|10@1+ (0.00200000000000000004163336342344337026588618755340576171875,-1.0220000000000000195399252334027551114559173583984375) [-1.02200000|1.02400000] "rad" ADC
SG_ ARS_RDI_ElevationAng_Clu_025 : 117|7@1+ (0.005000000000000000104083408558608425664715468883514404296875,-0.315000000000000002220446049250313080847263336181640625) [-0.31500000|0.32000000] "rad" ADC
SG_ ARS_RDI_RCS_Clu_025 : 124|9@1+ (0.200000000000000011102230246251565404236316680908203125,-51.10000000000000142108547152020037174224853515625) [-51.10000000|51.10000000] "dBsm" ADC
SG_ ARS_RDI_SNR_Clu_025 : 133|7@1+ (0.5,0) [0E-008|63.50000000] "dB" ADC
SG_ ARS_RDI_DynProp_Clu_025 : 140|2@1+ (1,0) [0E-008|3.00000000] "unitless" ADC
SG_ ARS_RDI_Quality_Clu_025 : 142|2@1+ (1,0) [0E-008|3.00000000] "unitless" ADC
SG_ ARS_RDI_Range_Clu_026 : 144|12@1+ (0.0625,0) [0E-008|255.93750000] "m" ADC
SG_ ARS_RDI_VradRel_Clu_026 : 156|11@1+ (0.1000000000000000055511151231257827021181583404541015625,-120) [-120.00000000|84.70000000] "m/s" ADC
SG_ ARS_RDI_AzimuthAng_Clu_026 : 167|10@1+ (0.00200000000000000004163336342344337026588618755340576171875,-1.0220000000000000195399252334027551114559173583984375) [-1.02200000|1.02400000] "rad" ADC
SG_ ARS_RDI_ElevationAng_Clu_026 : 177|7@1+ (0.005000000000000000104083408558608425664715468883514404296875,-0.315000000000000002220446049250313080847263336181640625) [-0.31500000|0.32000000] "rad" ADC
SG_ ARS_RDI_RCS_Clu_026 : 184|9@1+ (0.200000000000000011102230246251565404236316680908203125,-51.10000000000000142108547152020037174224853515625) [-51.10000000|51.10000000] "dBsm" ADC
SG_ ARS_RDI_SNR_Clu_026 : 193|7@1+ (0.5,0) [0E-008|63.50000000] "dB" ADC
SG_ ARS_RDI_DynProp_Clu_026 : 200|2@1+ (1,0) [0E-008|3.00000000] "unitless" ADC
SG_ ARS_RDI_Quality_Clu_026 : 202|2@1+ (1,0) [0E-008|3.00000000] "unitless" ADC
SG_ ARS_RDI_Range_Clu_027 : 204|12@1+ (0.0625,0) [0E-008|255.93750000] "m" ADC
SG_ ARS_RDI_VradRel_Clu_027 : 216|11@1+ (0.1000000000000000055511151231257827021181583404541015625,-120) [-120.00000000|84.70000000] "m/s" ADC
SG_ ARS_RDI_AzimuthAng_Clu_027 : 227|10@1+ (0.00200000000000000004163336342344337026588618755340576171875,-1.0220000000000000195399252334027551114559173583984375) [-1.02200000|1.02400000] "rad" ADC
SG_ ARS_RDI_ElevationAng_Clu_027 : 237|7@1+ (0.005000000000000000104083408558608425664715468883514404296875,-0.315000000000000002220446049250313080847263336181640625) [-0.31500000|0.32000000] "rad" ADC
SG_ ARS_RDI_RCS_Clu_027 : 244|9@1+ (0.200000000000000011102230246251565404236316680908203125,-51.10000000000000142108547152020037174224853515625) [-51.10000000|51.10000000] "dBsm" ADC
SG_ ARS_RDI_SNR_Clu_027 : 253|7@1+ (0.5,0) [0E-008|63.50000000] "dB" ADC
SG_ ARS_RDI_DynProp_Clu_027 : 260|2@1+ (1,0) [0E-008|3.00000000] "unitless" ADC
SG_ ARS_RDI_Quality_Clu_027 : 262|2@1+ (1,0) [0E-008|3.00000000] "unitless" ADC
SG_ ARS_RDI_Range_Clu_028 : 264|12@1+ (0.0625,0) [0E-008|255.93750000] "m" ADC
SG_ ARS_RDI_VradRel_Clu_028 : 276|11@1+ (0.1000000000000000055511151231257827021181583404541015625,-120) [-120.00000000|84.70000000] "m/s" ADC
SG_ ARS_RDI_AzimuthAng_Clu_028 : 287|10@1+ (0.00200000000000000004163336342344337026588618755340576171875,-1.0220000000000000195399252334027551114559173583984375) [-1.02200000|1.02400000] "rad" ADC
SG_ ARS_RDI_ElevationAng_Clu_028 : 297|7@1+ (0.005000000000000000104083408558608425664715468883514404296875,-0.315000000000000002220446049250313080847263336181640625) [-0.31500000|0.32000000] "rad" ADC
SG_ ARS_RDI_RCS_Clu_028 : 304|9@1+ (0.200000000000000011102230246251565404236316680908203125,-51.10000000000000142108547152020037174224853515625) [-51.10000000|51.10000000] "dBsm" ADC
SG_ ARS_RDI_SNR_Clu_028 : 313|7@1+ (0.5,0) [0E-008|63.50000000] "dB" ADC
SG_ ARS_RDI_DynProp_Clu_028 : 320|2@1+ (1,0) [0E-008|3.00000000] "unitless" ADC
SG_ ARS_RDI_Quality_Clu_028 : 322|2@1+ (1,0) [0E-008|3.00000000] "unitless" ADC
SG_ ARS_RDI_Range_Clu_029 : 324|12@1+ (0.0625,0) [0E-008|255.93750000] "m" ADC
SG_ ARS_RDI_VradRel_Clu_029 : 336|11@1+ (0.1000000000000000055511151231257827021181583404541015625,-120) [-120.00000000|84.70000000] "m/s" ADC
SG_ ARS_RDI_AzimuthAng_Clu_029 : 347|10@1+ (0.00200000000000000004163336342344337026588618755340576171875,-1.0220000000000000195399252334027551114559173583984375) [-1.02200000|1.02400000] "rad" ADC
SG_ ARS_RDI_ElevationAng_Clu_029 : 357|7@1+ (0.005000000000000000104083408558608425664715468883514404296875,-0.315000000000000002220446049250313080847263336181640625) [-0.31500000|0.32000000] "rad" ADC
SG_ ARS_RDI_RCS_Clu_029 : 364|9@1+ (0.200000000000000011102230246251565404236316680908203125,-51.10000000000000142108547152020037174224853515625) [-51.10000000|51.10000000] "dBsm" ADC
SG_ ARS_RDI_SNR_Clu_029 : 373|7@1+ (0.5,0) [0E-008|63.50000000] "dB" ADC
SG_ ARS_RDI_DynProp_Clu_029 : 380|2@1+ (1,0) [0E-008|3.00000000] "unitless" ADC
SG_ ARS_RDI_Quality_Clu_029 : 382|2@1+ (1,0) [0E-008|3.00000000] "unitless" ADC
SG_ ARS_RDI_Range_Clu_030 : 384|12@1+ (0.0625,0) [0E-008|255.93750000] "m" ADC
SG_ ARS_RDI_VradRel_Clu_030 : 396|11@1+ (0.1000000000000000055511151231257827021181583404541015625,-120) [-120.00000000|84.70000000] "m/s" ADC
SG_ ARS_RDI_AzimuthAng_Clu_030 : 407|10@1+ (0.00200000000000000004163336342344337026588618755340576171875,-1.0220000000000000195399252334027551114559173583984375) [-1.02200000|1.02400000] "rad" ADC
SG_ ARS_RDI_ElevationAng_Clu_030 : 417|7@1+ (0.005000000000000000104083408558608425664715468883514404296875,-0.315000000000000002220446049250313080847263336181640625) [-0.31500000|0.32000000] "rad" ADC
SG_ ARS_RDI_RCS_Clu_030 : 424|9@1+ (0.200000000000000011102230246251565404236316680908203125,-51.10000000000000142108547152020037174224853515625) [-51.10000000|51.10000000] "dBsm" ADC
SG_ ARS_RDI_SNR_Clu_030 : 433|7@1+ (0.5,0) [0E-008|63.50000000] "dB" ADC
SG_ ARS_RDI_DynProp_Clu_030 : 440|2@1+ (1,0) [0E-008|3.00000000] "unitless" ADC
SG_ ARS_RDI_Quality_Clu_030 : 442|2@1+ (1,0) [0E-008|3.00000000] "unitless" ADC
SG_ ARS_RDI_Range_Clu_031 : 444|12@1+ (0.0625,0) [0E-008|255.93750000] "m" ADC
SG_ ARS_RDI_VradRel_Clu_031 : 456|11@1+ (0.1000000000000000055511151231257827021181583404541015625,-120) [-120.00000000|84.70000000] "m/s" ADC
SG_ ARS_RDI_AzimuthAng_Clu_031 : 467|10@1+ (0.00200000000000000004163336342344337026588618755340576171875,-1.0220000000000000195399252334027551114559173583984375) [-1.02200000|1.02400000] "rad" ADC
SG_ ARS_RDI_ElevationAng_Clu_031 : 477|7@1+ (0.005000000000000000104083408558608425664715468883514404296875,-0.315000000000000002220446049250313080847263336181640625) [-0.31500000|0.32000000] "rad" ADC
SG_ ARS_RDI_RCS_Clu_031 : 484|9@1+ (0.200000000000000011102230246251565404236316680908203125,-51.10000000000000142108547152020037174224853515625) [-51.10000000|51.10000000] "dBsm" ADC
SG_ ARS_RDI_SNR_Clu_031 : 493|7@1+ (0.5,0) [0E-008|63.50000000] "dB" ADC
SG_ ARS_RDI_DynProp_Clu_031 : 500|2@1+ (1,0) [0E-008|3.00000000] "unitless" ADC
SG_ ARS_RDI_Quality_Clu_031 : 502|2@1+ (1,0) [0E-008|3.00000000] "unitless" ADC
BO_ 1604 MRR_0x644: 64 MRR
SG_ Checksum_605_S : 0|16@1+ (1,0) [0E-008|65535.00000000] "" ADC
SG_ Counter_605_S : 16|8@1+ (1,0) [0E-008|255.00000000] "" ADC
SG_ ARS_RDI_Range_Clu_032 : 24|12@1+ (0.0625,0) [0E-008|255.93750000] "m" ADC
SG_ ARS_RDI_VradRel_Clu_032 : 36|11@1+ (0.1000000000000000055511151231257827021181583404541015625,-120) [-120.00000000|84.70000000] "m/s" ADC
SG_ ARS_RDI_AzimuthAng_Clu_032 : 47|10@1+ (0.00200000000000000004163336342344337026588618755340576171875,-1.0220000000000000195399252334027551114559173583984375) [-1.02200000|1.02400000] "rad" ADC
SG_ ARS_RDI_ElevationAng_Clu_032 : 57|7@1+ (0.005000000000000000104083408558608425664715468883514404296875,-0.315000000000000002220446049250313080847263336181640625) [-0.31500000|0.32000000] "rad" ADC
SG_ ARS_RDI_RCS_Clu_032 : 64|9@1+ (0.200000000000000011102230246251565404236316680908203125,-51.10000000000000142108547152020037174224853515625) [-51.10000000|51.10000000] "dBsm" ADC
SG_ ARS_RDI_SNR_Clu_032 : 73|7@1+ (0.5,0) [0E-008|63.50000000] "dB" ADC
SG_ ARS_RDI_DynProp_Clu_032 : 80|2@1+ (1,0) [0E-008|3.00000000] "unitless" ADC
SG_ ARS_RDI_Quality_Clu_032 : 82|2@1+ (1,0) [0E-008|3.00000000] "unitless" ADC
SG_ ARS_RDI_Range_Clu_033 : 84|12@1+ (0.0625,0) [0E-008|255.93750000] "m" ADC
SG_ ARS_RDI_VradRel_Clu_033 : 96|11@1+ (0.1000000000000000055511151231257827021181583404541015625,-120) [-120.00000000|84.70000000] "m/s" ADC
SG_ ARS_RDI_AzimuthAng_Clu_033 : 107|10@1+ (0.00200000000000000004163336342344337026588618755340576171875,-1.0220000000000000195399252334027551114559173583984375) [-1.02200000|1.02400000] "rad" ADC
SG_ ARS_RDI_ElevationAng_Clu_033 : 117|7@1+ (0.005000000000000000104083408558608425664715468883514404296875,-0.315000000000000002220446049250313080847263336181640625) [-0.31500000|0.32000000] "rad" ADC
SG_ ARS_RDI_RCS_Clu_033 : 124|9@1+ (0.200000000000000011102230246251565404236316680908203125,-51.10000000000000142108547152020037174224853515625) [-51.10000000|51.10000000] "dBsm" ADC
SG_ ARS_RDI_SNR_Clu_033 : 133|7@1+ (0.5,0) [0E-008|63.50000000] "dB" ADC
SG_ ARS_RDI_DynProp_Clu_033 : 140|2@1+ (1,0) [0E-008|3.00000000] "unitless" ADC
SG_ ARS_RDI_Quality_Clu_033 : 142|2@1+ (1,0) [0E-008|3.00000000] "unitless" ADC
SG_ ARS_RDI_Range_Clu_034 : 144|12@1+ (0.0625,0) [0E-008|255.93750000] "m" ADC
SG_ ARS_RDI_VradRel_Clu_034 : 156|11@1+ (0.1000000000000000055511151231257827021181583404541015625,-120) [-120.00000000|84.70000000] "m/s" ADC
SG_ ARS_RDI_AzimuthAng_Clu_034 : 167|10@1+ (0.00200000000000000004163336342344337026588618755340576171875,-1.0220000000000000195399252334027551114559173583984375) [-1.02200000|1.02400000] "rad" ADC
SG_ ARS_RDI_ElevationAng_Clu_034 : 177|7@1+ (0.005000000000000000104083408558608425664715468883514404296875,-0.315000000000000002220446049250313080847263336181640625) [-0.31500000|0.32000000] "rad" ADC
SG_ ARS_RDI_RCS_Clu_034 : 184|9@1+ (0.200000000000000011102230246251565404236316680908203125,-51.10000000000000142108547152020037174224853515625) [-51.10000000|51.10000000] "dBsm" ADC
SG_ ARS_RDI_SNR_Clu_034 : 193|7@1+ (0.5,0) [0E-008|63.50000000] "dB" ADC
SG_ ARS_RDI_DynProp_Clu_034 : 200|2@1+ (1,0) [0E-008|3.00000000] "unitless" ADC
SG_ ARS_RDI_Quality_Clu_034 : 202|2@1+ (1,0) [0E-008|3.00000000] "unitless" ADC
SG_ ARS_RDI_Range_Clu_035 : 204|12@1+ (0.0625,0) [0E-008|255.93750000] "m" ADC
SG_ ARS_RDI_VradRel_Clu_035 : 216|11@1+ (0.1000000000000000055511151231257827021181583404541015625,-120) [-120.00000000|84.70000000] "m/s" ADC
SG_ ARS_RDI_AzimuthAng_Clu_035 : 227|10@1+ (0.00200000000000000004163336342344337026588618755340576171875,-1.0220000000000000195399252334027551114559173583984375) [-1.02200000|1.02400000] "rad" ADC
SG_ ARS_RDI_ElevationAng_Clu_035 : 237|7@1+ (0.005000000000000000104083408558608425664715468883514404296875,-0.315000000000000002220446049250313080847263336181640625) [-0.31500000|0.32000000] "rad" ADC
SG_ ARS_RDI_RCS_Clu_035 : 244|9@1+ (0.200000000000000011102230246251565404236316680908203125,-51.10000000000000142108547152020037174224853515625) [-51.10000000|51.10000000] "dBsm" ADC
SG_ ARS_RDI_SNR_Clu_035 : 253|7@1+ (0.5,0) [0E-008|63.50000000] "dB" ADC
SG_ ARS_RDI_DynProp_Clu_035 : 260|2@1+ (1,0) [0E-008|3.00000000] "unitless" ADC
SG_ ARS_RDI_Quality_Clu_035 : 262|2@1+ (1,0) [0E-008|3.00000000] "unitless" ADC
SG_ ARS_RDI_Range_Clu_036 : 264|12@1+ (0.0625,0) [0E-008|255.93750000] "m" ADC
SG_ ARS_RDI_VradRel_Clu_036 : 276|11@1+ (0.1000000000000000055511151231257827021181583404541015625,-120) [-120.00000000|84.70000000] "m/s" ADC
SG_ ARS_RDI_AzimuthAng_Clu_036 : 287|10@1+ (0.00200000000000000004163336342344337026588618755340576171875,-1.0220000000000000195399252334027551114559173583984375) [-1.02200000|1.02400000] "rad" ADC
SG_ ARS_RDI_ElevationAng_Clu_036 : 297|7@1+ (0.005000000000000000104083408558608425664715468883514404296875,-0.315000000000000002220446049250313080847263336181640625) [-0.31500000|0.32000000] "rad" ADC
SG_ ARS_RDI_RCS_Clu_036 : 304|9@1+ (0.200000000000000011102230246251565404236316680908203125,-51.10000000000000142108547152020037174224853515625) [-51.10000000|51.10000000] "dBsm" ADC
SG_ ARS_RDI_SNR_Clu_036 : 313|7@1+ (0.5,0) [0E-008|63.50000000] "dB" ADC
SG_ ARS_RDI_DynProp_Clu_036 : 320|2@1+ (1,0) [0E-008|3.00000000] "unitless" ADC
SG_ ARS_RDI_Quality_Clu_036 : 322|2@1+ (1,0) [0E-008|3.00000000] "unitless" ADC
SG_ ARS_RDI_Range_Clu_037 : 324|12@1+ (0.0625,0) [0E-008|255.93750000] "m" ADC
SG_ ARS_RDI_VradRel_Clu_037 : 336|11@1+ (0.1000000000000000055511151231257827021181583404541015625,-120) [-120.00000000|84.70000000] "m/s" ADC
SG_ ARS_RDI_AzimuthAng_Clu_037 : 347|10@1+ (0.00200000000000000004163336342344337026588618755340576171875,-1.0220000000000000195399252334027551114559173583984375) [-1.02200000|1.02400000] "rad" ADC
SG_ ARS_RDI_ElevationAng_Clu_037 : 357|7@1+ (0.005000000000000000104083408558608425664715468883514404296875,-0.315000000000000002220446049250313080847263336181640625) [-0.31500000|0.32000000] "rad" ADC
SG_ ARS_RDI_RCS_Clu_037 : 364|9@1+ (0.200000000000000011102230246251565404236316680908203125,-51.10000000000000142108547152020037174224853515625) [-51.10000000|51.10000000] "dBsm" ADC
SG_ ARS_RDI_SNR_Clu_037 : 373|7@1+ (0.5,0) [0E-008|63.50000000] "dB" ADC
SG_ ARS_RDI_DynProp_Clu_037 : 380|2@1+ (1,0) [0E-008|3.00000000] "unitless" ADC
SG_ ARS_RDI_Quality_Clu_037 : 382|2@1+ (1,0) [0E-008|3.00000000] "unitless" ADC
SG_ ARS_RDI_Range_Clu_038 : 384|12@1+ (0.0625,0) [0E-008|255.93750000] "m" ADC
SG_ ARS_RDI_VradRel_Clu_038 : 396|11@1+ (0.1000000000000000055511151231257827021181583404541015625,-120) [-120.00000000|84.70000000] "m/s" ADC
SG_ ARS_RDI_AzimuthAng_Clu_038 : 407|10@1+ (0.00200000000000000004163336342344337026588618755340576171875,-1.0220000000000000195399252334027551114559173583984375) [-1.02200000|1.02400000] "rad" ADC
SG_ ARS_RDI_ElevationAng_Clu_038 : 417|7@1+ (0.005000000000000000104083408558608425664715468883514404296875,-0.315000000000000002220446049250313080847263336181640625) [-0.31500000|0.32000000] "rad" ADC
SG_ ARS_RDI_RCS_Clu_038 : 424|9@1+ (0.200000000000000011102230246251565404236316680908203125,-51.10000000000000142108547152020037174224853515625) [-51.10000000|51.10000000] "dBsm" ADC
SG_ ARS_RDI_SNR_Clu_038 : 433|7@1+ (0.5,0) [0E-008|63.50000000] "dB" ADC
SG_ ARS_RDI_DynProp_Clu_038 : 440|2@1+ (1,0) [0E-008|3.00000000] "unitless" ADC
SG_ ARS_RDI_Quality_Clu_038 : 442|2@1+ (1,0) [0E-008|3.00000000] "unitless" ADC
SG_ ARS_RDI_Range_Clu_039 : 444|12@1+ (0.0625,0) [0E-008|255.93750000] "m" ADC
SG_ ARS_RDI_VradRel_Clu_039 : 456|11@1+ (0.1000000000000000055511151231257827021181583404541015625,-120) [-120.00000000|84.70000000] "m/s" ADC
SG_ ARS_RDI_AzimuthAng_Clu_039 : 467|10@1+ (0.00200000000000000004163336342344337026588618755340576171875,-1.0220000000000000195399252334027551114559173583984375) [-1.02200000|1.02400000] "rad" ADC
SG_ ARS_RDI_ElevationAng_Clu_039 : 477|7@1+ (0.005000000000000000104083408558608425664715468883514404296875,-0.315000000000000002220446049250313080847263336181640625) [-0.31500000|0.32000000] "rad" ADC
SG_ ARS_RDI_RCS_Clu_039 : 484|9@1+ (0.200000000000000011102230246251565404236316680908203125,-51.10000000000000142108547152020037174224853515625) [-51.10000000|51.10000000] "dBsm" ADC
SG_ ARS_RDI_SNR_Clu_039 : 493|7@1+ (0.5,0) [0E-008|63.50000000] "dB" ADC
SG_ ARS_RDI_DynProp_Clu_039 : 500|2@1+ (1,0) [0E-008|3.00000000] "unitless" ADC
SG_ ARS_RDI_Quality_Clu_039 : 502|2@1+ (1,0) [0E-008|3.00000000] "unitless" ADC
BO_ 1605 MRR_0x645: 64 MRR
SG_ Checksum_606_S : 0|16@1+ (1,0) [0E-008|65535.00000000] "" ADC
SG_ Counter_606_S : 16|8@1+ (1,0) [0E-008|255.00000000] "" ADC
SG_ ARS_RDI_Range_Clu_040 : 24|12@1+ (0.0625,0) [0E-008|255.93750000] "m" ADC
SG_ ARS_RDI_VradRel_Clu_040 : 36|11@1+ (0.1000000000000000055511151231257827021181583404541015625,-120) [-120.00000000|84.70000000] "m/s" ADC
SG_ ARS_RDI_AzimuthAng_Clu_040 : 47|10@1+ (0.00200000000000000004163336342344337026588618755340576171875,-1.0220000000000000195399252334027551114559173583984375) [-1.02200000|1.02400000] "rad" ADC
SG_ ARS_RDI_ElevationAng_Clu_040 : 57|7@1+ (0.005000000000000000104083408558608425664715468883514404296875,-0.315000000000000002220446049250313080847263336181640625) [-0.31500000|0.32000000] "rad" ADC
SG_ ARS_RDI_RCS_Clu_040 : 64|9@1+ (0.200000000000000011102230246251565404236316680908203125,-51.10000000000000142108547152020037174224853515625) [-51.10000000|51.10000000] "dBsm" ADC
SG_ ARS_RDI_SNR_Clu_040 : 73|7@1+ (0.5,0) [0E-008|63.50000000] "dB" ADC
SG_ ARS_RDI_DynProp_Clu_040 : 80|2@1+ (1,0) [0E-008|3.00000000] "unitless" ADC
SG_ ARS_RDI_Quality_Clu_040 : 82|2@1+ (1,0) [0E-008|3.00000000] "unitless" ADC
SG_ ARS_RDI_Range_Clu_041 : 84|12@1+ (0.0625,0) [0E-008|255.93750000] "m" ADC
SG_ ARS_RDI_VradRel_Clu_041 : 96|11@1+ (0.1000000000000000055511151231257827021181583404541015625,-120) [-120.00000000|84.70000000] "m/s" ADC
SG_ ARS_RDI_AzimuthAng_Clu_041 : 107|10@1+ (0.00200000000000000004163336342344337026588618755340576171875,-1.0220000000000000195399252334027551114559173583984375) [-1.02200000|1.02400000] "rad" ADC
SG_ ARS_RDI_ElevationAng_Clu_041 : 117|7@1+ (0.005000000000000000104083408558608425664715468883514404296875,-0.315000000000000002220446049250313080847263336181640625) [-0.31500000|0.32000000] "rad" ADC
SG_ ARS_RDI_RCS_Clu_041 : 124|9@1+ (0.200000000000000011102230246251565404236316680908203125,-51.10000000000000142108547152020037174224853515625) [-51.10000000|51.10000000] "dBsm" ADC
SG_ ARS_RDI_SNR_Clu_041 : 133|7@1+ (0.5,0) [0E-008|63.50000000] "dB" ADC
SG_ ARS_RDI_DynProp_Clu_041 : 140|2@1+ (1,0) [0E-008|3.00000000] "unitless" ADC
SG_ ARS_RDI_Quality_Clu_041 : 142|2@1+ (1,0) [0E-008|3.00000000] "unitless" ADC
SG_ ARS_RDI_Range_Clu_042 : 144|12@1+ (0.0625,0) [0E-008|255.93750000] "m" ADC
SG_ ARS_RDI_VradRel_Clu_042 : 156|11@1+ (0.1000000000000000055511151231257827021181583404541015625,-120) [-120.00000000|84.70000000] "m/s" ADC
SG_ ARS_RDI_AzimuthAng_Clu_042 : 167|10@1+ (0.00200000000000000004163336342344337026588618755340576171875,-1.0220000000000000195399252334027551114559173583984375) [-1.02200000|1.02400000] "rad" ADC
SG_ ARS_RDI_ElevationAng_Clu_042 : 177|7@1+ (0.005000000000000000104083408558608425664715468883514404296875,-0.315000000000000002220446049250313080847263336181640625) [-0.31500000|0.32000000] "rad" ADC
SG_ ARS_RDI_RCS_Clu_042 : 184|9@1+ (0.200000000000000011102230246251565404236316680908203125,-51.10000000000000142108547152020037174224853515625) [-51.10000000|51.10000000] "dBsm" ADC
SG_ ARS_RDI_SNR_Clu_042 : 193|7@1+ (0.5,0) [0E-008|63.50000000] "dB" ADC
SG_ ARS_RDI_DynProp_Clu_042 : 200|2@1+ (1,0) [0E-008|3.00000000] "unitless" ADC
SG_ ARS_RDI_Quality_Clu_042 : 202|2@1+ (1,0) [0E-008|3.00000000] "unitless" ADC
SG_ ARS_RDI_Range_Clu_043 : 204|12@1+ (0.0625,0) [0E-008|255.93750000] "m" ADC
SG_ ARS_RDI_VradRel_Clu_043 : 216|11@1+ (0.1000000000000000055511151231257827021181583404541015625,-120) [-120.00000000|84.70000000] "m/s" ADC
SG_ ARS_RDI_AzimuthAng_Clu_043 : 227|10@1+ (0.00200000000000000004163336342344337026588618755340576171875,-1.0220000000000000195399252334027551114559173583984375) [-1.02200000|1.02400000] "rad" ADC
SG_ ARS_RDI_ElevationAng_Clu_043 : 237|7@1+ (0.005000000000000000104083408558608425664715468883514404296875,-0.315000000000000002220446049250313080847263336181640625) [-0.31500000|0.32000000] "rad" ADC
SG_ ARS_RDI_RCS_Clu_043 : 244|9@1+ (0.200000000000000011102230246251565404236316680908203125,-51.10000000000000142108547152020037174224853515625) [-51.10000000|51.10000000] "dBsm" ADC
SG_ ARS_RDI_SNR_Clu_043 : 253|7@1+ (0.5,0) [0E-008|63.50000000] "dB" ADC
SG_ ARS_RDI_DynProp_Clu_043 : 260|2@1+ (1,0) [0E-008|3.00000000] "unitless" ADC
SG_ ARS_RDI_Quality_Clu_043 : 262|2@1+ (1,0) [0E-008|3.00000000] "unitless" ADC
SG_ ARS_RDI_Range_Clu_044 : 264|12@1+ (0.0625,0) [0E-008|255.93750000] "m" ADC
SG_ ARS_RDI_VradRel_Clu_044 : 276|11@1+ (0.1000000000000000055511151231257827021181583404541015625,-120) [-120.00000000|84.70000000] "m/s" ADC
SG_ ARS_RDI_AzimuthAng_Clu_044 : 287|10@1+ (0.00200000000000000004163336342344337026588618755340576171875,-1.0220000000000000195399252334027551114559173583984375) [-1.02200000|1.02400000] "rad" ADC
SG_ ARS_RDI_ElevationAng_Clu_044 : 297|7@1+ (0.005000000000000000104083408558608425664715468883514404296875,-0.315000000000000002220446049250313080847263336181640625) [-0.31500000|0.32000000] "rad" ADC
SG_ ARS_RDI_RCS_Clu_044 : 304|9@1+ (0.200000000000000011102230246251565404236316680908203125,-51.10000000000000142108547152020037174224853515625) [-51.10000000|51.10000000] "dBsm" ADC
SG_ ARS_RDI_SNR_Clu_044 : 313|7@1+ (0.5,0) [0E-008|63.50000000] "dB" ADC
SG_ ARS_RDI_DynProp_Clu_044 : 320|2@1+ (1,0) [0E-008|3.00000000] "unitless" ADC
SG_ ARS_RDI_Quality_Clu_044 : 322|2@1+ (1,0) [0E-008|3.00000000] "unitless" ADC
SG_ ARS_RDI_Range_Clu_045 : 324|12@1+ (0.0625,0) [0E-008|255.93750000] "m" ADC
SG_ ARS_RDI_VradRel_Clu_045 : 336|11@1+ (0.1000000000000000055511151231257827021181583404541015625,-120) [-120.00000000|84.70000000] "m/s" ADC
SG_ ARS_RDI_AzimuthAng_Clu_045 : 347|10@1+ (0.00200000000000000004163336342344337026588618755340576171875,-1.0220000000000000195399252334027551114559173583984375) [-1.02200000|1.02400000] "rad" ADC
SG_ ARS_RDI_ElevationAng_Clu_045 : 357|7@1+ (0.005000000000000000104083408558608425664715468883514404296875,-0.315000000000000002220446049250313080847263336181640625) [-0.31500000|0.32000000] "rad" ADC
SG_ ARS_RDI_RCS_Clu_045 : 364|9@1+ (0.200000000000000011102230246251565404236316680908203125,-51.10000000000000142108547152020037174224853515625) [-51.10000000|51.10000000] "dBsm" ADC
SG_ ARS_RDI_SNR_Clu_045 : 373|7@1+ (0.5,0) [0E-008|63.50000000] "dB" ADC
SG_ ARS_RDI_DynProp_Clu_045 : 380|2@1+ (1,0) [0E-008|3.00000000] "unitless" ADC
SG_ ARS_RDI_Quality_Clu_045 : 382|2@1+ (1,0) [0E-008|3.00000000] "unitless" ADC
SG_ ARS_RDI_Range_Clu_046 : 384|12@1+ (0.0625,0) [0E-008|255.93750000] "m" ADC
SG_ ARS_RDI_VradRel_Clu_046 : 396|11@1+ (0.1000000000000000055511151231257827021181583404541015625,-120) [-120.00000000|84.70000000] "m/s" ADC
SG_ ARS_RDI_AzimuthAng_Clu_046 : 407|10@1+ (0.00200000000000000004163336342344337026588618755340576171875,-1.0220000000000000195399252334027551114559173583984375) [-1.02200000|1.02400000] "rad" ADC
SG_ ARS_RDI_ElevationAng_Clu_046 : 417|7@1+ (0.005000000000000000104083408558608425664715468883514404296875,-0.315000000000000002220446049250313080847263336181640625) [-0.31500000|0.32000000] "rad" ADC
SG_ ARS_RDI_RCS_Clu_046 : 424|9@1+ (0.200000000000000011102230246251565404236316680908203125,-51.10000000000000142108547152020037174224853515625) [-51.10000000|51.10000000] "dBsm" ADC
SG_ ARS_RDI_SNR_Clu_046 : 433|7@1+ (0.5,0) [0E-008|63.50000000] "dB" ADC
SG_ ARS_RDI_DynProp_Clu_046 : 440|2@1+ (1,0) [0E-008|3.00000000] "unitless" ADC
SG_ ARS_RDI_Quality_Clu_046 : 442|2@1+ (1,0) [0E-008|3.00000000] "unitless" ADC
SG_ ARS_RDI_Range_Clu_047 : 444|12@1+ (0.0625,0) [0E-008|255.93750000] "m" ADC
SG_ ARS_RDI_VradRel_Clu_047 : 456|11@1+ (0.1000000000000000055511151231257827021181583404541015625,-120) [-120.00000000|84.70000000] "m/s" ADC
SG_ ARS_RDI_AzimuthAng_Clu_047 : 467|10@1+ (0.00200000000000000004163336342344337026588618755340576171875,-1.0220000000000000195399252334027551114559173583984375) [-1.02200000|1.02400000] "rad" ADC
SG_ ARS_RDI_ElevationAng_Clu_047 : 477|7@1+ (0.005000000000000000104083408558608425664715468883514404296875,-0.315000000000000002220446049250313080847263336181640625) [-0.31500000|0.32000000] "rad" ADC
SG_ ARS_RDI_RCS_Clu_047 : 484|9@1+ (0.200000000000000011102230246251565404236316680908203125,-51.10000000000000142108547152020037174224853515625) [-51.10000000|51.10000000] "dBsm" ADC
SG_ ARS_RDI_SNR_Clu_047 : 493|7@1+ (0.5,0) [0E-008|63.50000000] "dB" ADC
SG_ ARS_RDI_DynProp_Clu_047 : 500|2@1+ (1,0) [0E-008|3.00000000] "unitless" ADC
SG_ ARS_RDI_Quality_Clu_047 : 502|2@1+ (1,0) [0E-008|3.00000000] "unitless" ADC
BO_ 1606 MRR_0x646: 64 MRR
SG_ Checksum_607_S : 0|16@1+ (1,0) [0E-008|65535.00000000] "" ADC
SG_ Counter_607_S : 16|8@1+ (1,0) [0E-008|255.00000000] "" ADC
SG_ ARS_RDI_Range_Clu_048 : 24|12@1+ (0.0625,0) [0E-008|255.93750000] "m" ADC
SG_ ARS_RDI_VradRel_Clu_048 : 36|11@1+ (0.1000000000000000055511151231257827021181583404541015625,-120) [-120.00000000|84.70000000] "m/s" ADC
SG_ ARS_RDI_AzimuthAng_Clu_048 : 47|10@1+ (0.00200000000000000004163336342344337026588618755340576171875,-1.0220000000000000195399252334027551114559173583984375) [-1.02200000|1.02400000] "rad" ADC
SG_ ARS_RDI_ElevationAng_Clu_048 : 57|7@1+ (0.005000000000000000104083408558608425664715468883514404296875,-0.315000000000000002220446049250313080847263336181640625) [-0.31500000|0.32000000] "rad" ADC
SG_ ARS_RDI_RCS_Clu_048 : 64|9@1+ (0.200000000000000011102230246251565404236316680908203125,-51.10000000000000142108547152020037174224853515625) [-51.10000000|51.10000000] "dBsm" ADC
SG_ ARS_RDI_SNR_Clu_048 : 73|7@1+ (0.5,0) [0E-008|63.50000000] "dB" ADC
SG_ ARS_RDI_DynProp_Clu_048 : 80|2@1+ (1,0) [0E-008|3.00000000] "unitless" ADC
SG_ ARS_RDI_Quality_Clu_048 : 82|2@1+ (1,0) [0E-008|3.00000000] "unitless" ADC
SG_ ARS_RDI_Range_Clu_049 : 84|12@1+ (0.0625,0) [0E-008|255.93750000] "m" ADC
SG_ ARS_RDI_VradRel_Clu_049 : 96|11@1+ (0.1000000000000000055511151231257827021181583404541015625,-120) [-120.00000000|84.70000000] "m/s" ADC
SG_ ARS_RDI_AzimuthAng_Clu_049 : 107|10@1+ (0.00200000000000000004163336342344337026588618755340576171875,-1.0220000000000000195399252334027551114559173583984375) [-1.02200000|1.02400000] "rad" ADC
SG_ ARS_RDI_ElevationAng_Clu_049 : 117|7@1+ (0.005000000000000000104083408558608425664715468883514404296875,-0.315000000000000002220446049250313080847263336181640625) [-0.31500000|0.32000000] "rad" ADC
SG_ ARS_RDI_RCS_Clu_049 : 124|9@1+ (0.200000000000000011102230246251565404236316680908203125,-51.10000000000000142108547152020037174224853515625) [-51.10000000|51.10000000] "dBsm" ADC
SG_ ARS_RDI_SNR_Clu_049 : 133|7@1+ (0.5,0) [0E-008|63.50000000] "dB" ADC
SG_ ARS_RDI_DynProp_Clu_049 : 140|2@1+ (1,0) [0E-008|3.00000000] "unitless" ADC
SG_ ARS_RDI_Quality_Clu_049 : 142|2@1+ (1,0) [0E-008|3.00000000] "unitless" ADC
SG_ ARS_RDI_Range_Clu_050 : 144|12@1+ (0.0625,0) [0E-008|255.93750000] "m" ADC
SG_ ARS_RDI_VradRel_Clu_050 : 156|11@1+ (0.1000000000000000055511151231257827021181583404541015625,-120) [-120.00000000|84.70000000] "m/s" ADC
SG_ ARS_RDI_AzimuthAng_Clu_050 : 167|10@1+ (0.00200000000000000004163336342344337026588618755340576171875,-1.0220000000000000195399252334027551114559173583984375) [-1.02200000|1.02400000] "rad" ADC
SG_ ARS_RDI_ElevationAng_Clu_050 : 177|7@1+ (0.005000000000000000104083408558608425664715468883514404296875,-0.315000000000000002220446049250313080847263336181640625) [-0.31500000|0.32000000] "rad" ADC
SG_ ARS_RDI_RCS_Clu_050 : 184|9@1+ (0.200000000000000011102230246251565404236316680908203125,-51.10000000000000142108547152020037174224853515625) [-51.10000000|51.10000000] "dBsm" ADC
SG_ ARS_RDI_SNR_Clu_050 : 193|7@1+ (0.5,0) [0E-008|63.50000000] "dB" ADC
SG_ ARS_RDI_DynProp_Clu_050 : 200|2@1+ (1,0) [0E-008|3.00000000] "unitless" ADC
SG_ ARS_RDI_Quality_Clu_050 : 202|2@1+ (1,0) [0E-008|3.00000000] "unitless" ADC
SG_ ARS_RDI_Range_Clu_051 : 204|12@1+ (0.0625,0) [0E-008|255.93750000] "m" ADC
SG_ ARS_RDI_VradRel_Clu_051 : 216|11@1+ (0.1000000000000000055511151231257827021181583404541015625,-120) [-120.00000000|84.70000000] "m/s" ADC
SG_ ARS_RDI_AzimuthAng_Clu_051 : 227|10@1+ (0.00200000000000000004163336342344337026588618755340576171875,-1.0220000000000000195399252334027551114559173583984375) [-1.02200000|1.02400000] "rad" ADC
SG_ ARS_RDI_ElevationAng_Clu_051 : 237|7@1+ (0.005000000000000000104083408558608425664715468883514404296875,-0.315000000000000002220446049250313080847263336181640625) [-0.31500000|0.32000000] "rad" ADC
SG_ ARS_RDI_RCS_Clu_051 : 244|9@1+ (0.200000000000000011102230246251565404236316680908203125,-51.10000000000000142108547152020037174224853515625) [-51.10000000|51.10000000] "dBsm" ADC
SG_ ARS_RDI_SNR_Clu_051 : 253|7@1+ (0.5,0) [0E-008|63.50000000] "dB" ADC
SG_ ARS_RDI_DynProp_Clu_051 : 260|2@1+ (1,0) [0E-008|3.00000000] "unitless" ADC
SG_ ARS_RDI_Quality_Clu_051 : 262|2@1+ (1,0) [0E-008|3.00000000] "unitless" ADC
SG_ ARS_RDI_Range_Clu_052 : 264|12@1+ (0.0625,0) [0E-008|255.93750000] "m" ADC
SG_ ARS_RDI_VradRel_Clu_052 : 276|11@1+ (0.1000000000000000055511151231257827021181583404541015625,-120) [-120.00000000|84.70000000] "m/s" ADC
SG_ ARS_RDI_AzimuthAng_Clu_052 : 287|10@1+ (0.00200000000000000004163336342344337026588618755340576171875,-1.0220000000000000195399252334027551114559173583984375) [-1.02200000|1.02400000] "rad" ADC
SG_ ARS_RDI_ElevationAng_Clu_052 : 297|7@1+ (0.005000000000000000104083408558608425664715468883514404296875,-0.315000000000000002220446049250313080847263336181640625) [-0.31500000|0.32000000] "rad" ADC
SG_ ARS_RDI_RCS_Clu_052 : 304|9@1+ (0.200000000000000011102230246251565404236316680908203125,-51.10000000000000142108547152020037174224853515625) [-51.10000000|51.10000000] "dBsm" ADC
SG_ ARS_RDI_SNR_Clu_052 : 313|7@1+ (0.5,0) [0E-008|63.50000000] "dB" ADC
SG_ ARS_RDI_DynProp_Clu_052 : 320|2@1+ (1,0) [0E-008|3.00000000] "unitless" ADC
SG_ ARS_RDI_Quality_Clu_052 : 322|2@1+ (1,0) [0E-008|3.00000000] "unitless" ADC
SG_ ARS_RDI_Range_Clu_053 : 324|12@1+ (0.0625,0) [0E-008|255.93750000] "m" ADC
SG_ ARS_RDI_VradRel_Clu_053 : 336|11@1+ (0.1000000000000000055511151231257827021181583404541015625,-120) [-120.00000000|84.70000000] "m/s" ADC
SG_ ARS_RDI_AzimuthAng_Clu_053 : 347|10@1+ (0.00200000000000000004163336342344337026588618755340576171875,-1.0220000000000000195399252334027551114559173583984375) [-1.02200000|1.02400000] "rad" ADC
SG_ ARS_RDI_ElevationAng_Clu_053 : 357|7@1+ (0.005000000000000000104083408558608425664715468883514404296875,-0.315000000000000002220446049250313080847263336181640625) [-0.31500000|0.32000000] "rad" ADC
SG_ ARS_RDI_RCS_Clu_053 : 364|9@1+ (0.200000000000000011102230246251565404236316680908203125,-51.10000000000000142108547152020037174224853515625) [-51.10000000|51.10000000] "dBsm" ADC
SG_ ARS_RDI_SNR_Clu_053 : 373|7@1+ (0.5,0) [0E-008|63.50000000] "dB" ADC
SG_ ARS_RDI_DynProp_Clu_053 : 380|2@1+ (1,0) [0E-008|3.00000000] "unitless" ADC
SG_ ARS_RDI_Quality_Clu_053 : 382|2@1+ (1,0) [0E-008|3.00000000] "unitless" ADC
SG_ ARS_RDI_Range_Clu_054 : 384|12@1+ (0.0625,0) [0E-008|255.93750000] "m" ADC
SG_ ARS_RDI_VradRel_Clu_054 : 396|11@1+ (0.1000000000000000055511151231257827021181583404541015625,-120) [-120.00000000|84.70000000] "m/s" ADC
SG_ ARS_RDI_AzimuthAng_Clu_054 : 407|10@1+ (0.00200000000000000004163336342344337026588618755340576171875,-1.0220000000000000195399252334027551114559173583984375) [-1.02200000|1.02400000] "rad" ADC
SG_ ARS_RDI_ElevationAng_Clu_054 : 417|7@1+ (0.005000000000000000104083408558608425664715468883514404296875,-0.315000000000000002220446049250313080847263336181640625) [-0.31500000|0.32000000] "rad" ADC
SG_ ARS_RDI_RCS_Clu_054 : 424|9@1+ (0.200000000000000011102230246251565404236316680908203125,-51.10000000000000142108547152020037174224853515625) [-51.10000000|51.10000000] "dBsm" ADC
SG_ ARS_RDI_SNR_Clu_054 : 433|7@1+ (0.5,0) [0E-008|63.50000000] "dB" ADC
SG_ ARS_RDI_DynProp_Clu_054 : 440|2@1+ (1,0) [0E-008|3.00000000] "unitless" ADC
SG_ ARS_RDI_Quality_Clu_054 : 442|2@1+ (1,0) [0E-008|3.00000000] "unitless" ADC
SG_ ARS_RDI_Range_Clu_055 : 444|12@1+ (0.0625,0) [0E-008|255.93750000] "m" ADC
SG_ ARS_RDI_VradRel_Clu_055 : 456|11@1+ (0.1000000000000000055511151231257827021181583404541015625,-120) [-120.00000000|84.70000000] "m/s" ADC
SG_ ARS_RDI_AzimuthAng_Clu_055 : 467|10@1+ (0.00200000000000000004163336342344337026588618755340576171875,-1.0220000000000000195399252334027551114559173583984375) [-1.02200000|1.02400000] "rad" ADC
SG_ ARS_RDI_ElevationAng_Clu_055 : 477|7@1+ (0.005000000000000000104083408558608425664715468883514404296875,-0.315000000000000002220446049250313080847263336181640625) [-0.31500000|0.32000000] "rad" ADC
SG_ ARS_RDI_RCS_Clu_055 : 484|9@1+ (0.200000000000000011102230246251565404236316680908203125,-51.10000000000000142108547152020037174224853515625) [-51.10000000|51.10000000] "dBsm" ADC
SG_ ARS_RDI_SNR_Clu_055 : 493|7@1+ (0.5,0) [0E-008|63.50000000] "dB" ADC
SG_ ARS_RDI_DynProp_Clu_055 : 500|2@1+ (1,0) [0E-008|3.00000000] "unitless" ADC
SG_ ARS_RDI_Quality_Clu_055 : 502|2@1+ (1,0) [0E-008|3.00000000] "unitless" ADC
BO_ 1607 MRR_0x647: 64 MRR
SG_ Checksum_608_S : 0|16@1+ (1,0) [0E-008|65535.00000000] "" ADC
SG_ Counter_608_S : 16|8@1+ (1,0) [0E-008|255.00000000] "" ADC
SG_ ARS_RDI_Range_Clu_056 : 24|12@1+ (0.0625,0) [0E-008|255.93750000] "m" ADC
SG_ ARS_RDI_VradRel_Clu_056 : 36|11@1+ (0.1000000000000000055511151231257827021181583404541015625,-120) [-120.00000000|84.70000000] "m/s" ADC
SG_ ARS_RDI_AzimuthAng_Clu_056 : 47|10@1+ (0.00200000000000000004163336342344337026588618755340576171875,-1.0220000000000000195399252334027551114559173583984375) [-1.02200000|1.02400000] "rad" ADC
SG_ ARS_RDI_ElevationAng_Clu_056 : 57|7@1+ (0.005000000000000000104083408558608425664715468883514404296875,-0.315000000000000002220446049250313080847263336181640625) [-0.31500000|0.32000000] "rad" ADC
SG_ ARS_RDI_RCS_Clu_056 : 64|9@1+ (0.200000000000000011102230246251565404236316680908203125,-51.10000000000000142108547152020037174224853515625) [-51.10000000|51.10000000] "dBsm" ADC
SG_ ARS_RDI_SNR_Clu_056 : 73|7@1+ (0.5,0) [0E-008|63.50000000] "dB" ADC
SG_ ARS_RDI_DynProp_Clu_056 : 80|2@1+ (1,0) [0E-008|3.00000000] "unitless" ADC
SG_ ARS_RDI_Quality_Clu_056 : 82|2@1+ (1,0) [0E-008|3.00000000] "unitless" ADC
SG_ ARS_RDI_Range_Clu_057 : 84|12@1+ (0.0625,0) [0E-008|255.93750000] "m" ADC
SG_ ARS_RDI_VradRel_Clu_057 : 96|11@1+ (0.1000000000000000055511151231257827021181583404541015625,-120) [-120.00000000|84.70000000] "m/s" ADC
SG_ ARS_RDI_AzimuthAng_Clu_057 : 107|10@1+ (0.00200000000000000004163336342344337026588618755340576171875,-1.0220000000000000195399252334027551114559173583984375) [-1.02200000|1.02400000] "rad" ADC
SG_ ARS_RDI_ElevationAng_Clu_057 : 117|7@1+ (0.005000000000000000104083408558608425664715468883514404296875,-0.315000000000000002220446049250313080847263336181640625) [-0.31500000|0.32000000] "rad" ADC
SG_ ARS_RDI_RCS_Clu_057 : 124|9@1+ (0.200000000000000011102230246251565404236316680908203125,-51.10000000000000142108547152020037174224853515625) [-51.10000000|51.10000000] "dBsm" ADC
SG_ ARS_RDI_SNR_Clu_057 : 133|7@1+ (0.5,0) [0E-008|63.50000000] "dB" ADC
SG_ ARS_RDI_DynProp_Clu_057 : 140|2@1+ (1,0) [0E-008|3.00000000] "unitless" ADC
SG_ ARS_RDI_Quality_Clu_057 : 142|2@1+ (1,0) [0E-008|3.00000000] "unitless" ADC
SG_ ARS_RDI_Range_Clu_058 : 144|12@1+ (0.0625,0) [0E-008|255.93750000] "m" ADC
SG_ ARS_RDI_VradRel_Clu_058 : 156|11@1+ (0.1000000000000000055511151231257827021181583404541015625,-120) [-120.00000000|84.70000000] "m/s" ADC
SG_ ARS_RDI_AzimuthAng_Clu_058 : 167|10@1+ (0.00200000000000000004163336342344337026588618755340576171875,-1.0220000000000000195399252334027551114559173583984375) [-1.02200000|1.02400000] "rad" ADC
SG_ ARS_RDI_ElevationAng_Clu_058 : 177|7@1+ (0.005000000000000000104083408558608425664715468883514404296875,-0.315000000000000002220446049250313080847263336181640625) [-0.31500000|0.32000000] "rad" ADC
SG_ ARS_RDI_RCS_Clu_058 : 184|9@1+ (0.200000000000000011102230246251565404236316680908203125,-51.10000000000000142108547152020037174224853515625) [-51.10000000|51.10000000] "dBsm" ADC
SG_ ARS_RDI_SNR_Clu_058 : 193|7@1+ (0.5,0) [0E-008|63.50000000] "dB" ADC
SG_ ARS_RDI_DynProp_Clu_058 : 200|2@1+ (1,0) [0E-008|3.00000000] "unitless" ADC
SG_ ARS_RDI_Quality_Clu_058 : 202|2@1+ (1,0) [0E-008|3.00000000] "unitless" ADC
SG_ ARS_RDI_Range_Clu_059 : 204|12@1+ (0.0625,0) [0E-008|255.93750000] "m" ADC
SG_ ARS_RDI_VradRel_Clu_059 : 216|11@1+ (0.1000000000000000055511151231257827021181583404541015625,-120) [-120.00000000|84.70000000] "m/s" ADC
SG_ ARS_RDI_AzimuthAng_Clu_059 : 227|10@1+ (0.00200000000000000004163336342344337026588618755340576171875,-1.0220000000000000195399252334027551114559173583984375) [-1.02200000|1.02400000] "rad" ADC
SG_ ARS_RDI_ElevationAng_Clu_059 : 237|7@1+ (0.005000000000000000104083408558608425664715468883514404296875,-0.315000000000000002220446049250313080847263336181640625) [-0.31500000|0.32000000] "rad" ADC
SG_ ARS_RDI_RCS_Clu_059 : 244|9@1+ (0.200000000000000011102230246251565404236316680908203125,-51.10000000000000142108547152020037174224853515625) [-51.10000000|51.10000000] "dBsm" ADC
SG_ ARS_RDI_SNR_Clu_059 : 253|7@1+ (0.5,0) [0E-008|63.50000000] "dB" ADC
SG_ ARS_RDI_DynProp_Clu_059 : 260|2@1+ (1,0) [0E-008|3.00000000] "unitless" ADC
SG_ ARS_RDI_Quality_Clu_059 : 262|2@1+ (1,0) [0E-008|3.00000000] "unitless" ADC
SG_ ARS_RDI_Range_Clu_060 : 264|12@1+ (0.0625,0) [0E-008|255.93750000] "m" ADC
SG_ ARS_RDI_VradRel_Clu_060 : 276|11@1+ (0.1000000000000000055511151231257827021181583404541015625,-120) [-120.00000000|84.70000000] "m/s" ADC
SG_ ARS_RDI_AzimuthAng_Clu_060 : 287|10@1+ (0.00200000000000000004163336342344337026588618755340576171875,-1.0220000000000000195399252334027551114559173583984375) [-1.02200000|1.02400000] "rad" ADC
SG_ ARS_RDI_ElevationAng_Clu_060 : 297|7@1+ (0.005000000000000000104083408558608425664715468883514404296875,-0.315000000000000002220446049250313080847263336181640625) [-0.31500000|0.32000000] "rad" ADC
SG_ ARS_RDI_RCS_Clu_060 : 304|9@1+ (0.200000000000000011102230246251565404236316680908203125,-51.10000000000000142108547152020037174224853515625) [-51.10000000|51.10000000] "dBsm" ADC
SG_ ARS_RDI_SNR_Clu_060 : 313|7@1+ (0.5,0) [0E-008|63.50000000] "dB" ADC
SG_ ARS_RDI_DynProp_Clu_060 : 320|2@1+ (1,0) [0E-008|3.00000000] "unitless" ADC
SG_ ARS_RDI_Quality_Clu_060 : 322|2@1+ (1,0) [0E-008|3.00000000] "unitless" ADC
SG_ ARS_RDI_Range_Clu_061 : 324|12@1+ (0.0625,0) [0E-008|255.93750000] "m" ADC
SG_ ARS_RDI_VradRel_Clu_061 : 336|11@1+ (0.1000000000000000055511151231257827021181583404541015625,-120) [-120.00000000|84.70000000] "m/s" ADC
SG_ ARS_RDI_AzimuthAng_Clu_061 : 347|10@1+ (0.00200000000000000004163336342344337026588618755340576171875,-1.0220000000000000195399252334027551114559173583984375) [-1.02200000|1.02400000] "rad" ADC
SG_ ARS_RDI_ElevationAng_Clu_061 : 357|7@1+ (0.005000000000000000104083408558608425664715468883514404296875,-0.315000000000000002220446049250313080847263336181640625) [-0.31500000|0.32000000] "rad" ADC
SG_ ARS_RDI_RCS_Clu_061 : 364|9@1+ (0.200000000000000011102230246251565404236316680908203125,-51.10000000000000142108547152020037174224853515625) [-51.10000000|51.10000000] "dBsm" ADC
SG_ ARS_RDI_SNR_Clu_061 : 373|7@1+ (0.5,0) [0E-008|63.50000000] "dB" ADC
SG_ ARS_RDI_DynProp_Clu_061 : 380|2@1+ (1,0) [0E-008|3.00000000] "unitless" ADC
SG_ ARS_RDI_Quality_Clu_061 : 382|2@1+ (1,0) [0E-008|3.00000000] "unitless" ADC
SG_ ARS_RDI_Range_Clu_062 : 384|12@1+ (0.0625,0) [0E-008|255.93750000] "m" ADC
SG_ ARS_RDI_VradRel_Clu_062 : 396|11@1+ (0.1000000000000000055511151231257827021181583404541015625,-120) [-120.00000000|84.70000000] "m/s" ADC
SG_ ARS_RDI_AzimuthAng_Clu_062 : 407|10@1+ (0.00200000000000000004163336342344337026588618755340576171875,-1.0220000000000000195399252334027551114559173583984375) [-1.02200000|1.02400000] "rad" ADC
SG_ ARS_RDI_ElevationAng_Clu_062 : 417|7@1+ (0.005000000000000000104083408558608425664715468883514404296875,-0.315000000000000002220446049250313080847263336181640625) [-0.31500000|0.32000000] "rad" ADC
SG_ ARS_RDI_RCS_Clu_062 : 424|9@1+ (0.200000000000000011102230246251565404236316680908203125,-51.10000000000000142108547152020037174224853515625) [-51.10000000|51.10000000] "dBsm" ADC
SG_ ARS_RDI_SNR_Clu_062 : 433|7@1+ (0.5,0) [0E-008|63.50000000] "dB" ADC
SG_ ARS_RDI_DynProp_Clu_062 : 440|2@1+ (1,0) [0E-008|3.00000000] "unitless" ADC
SG_ ARS_RDI_Quality_Clu_062 : 442|2@1+ (1,0) [0E-008|3.00000000] "unitless" ADC
SG_ ARS_RDI_Range_Clu_063 : 444|12@1+ (0.0625,0) [0E-008|255.93750000] "m" ADC
SG_ ARS_RDI_VradRel_Clu_063 : 456|11@1+ (0.1000000000000000055511151231257827021181583404541015625,-120) [-120.00000000|84.70000000] "m/s" ADC
SG_ ARS_RDI_AzimuthAng_Clu_063 : 467|10@1+ (0.00200000000000000004163336342344337026588618755340576171875,-1.0220000000000000195399252334027551114559173583984375) [-1.02200000|1.02400000] "rad" ADC
SG_ ARS_RDI_ElevationAng_Clu_063 : 477|7@1+ (0.005000000000000000104083408558608425664715468883514404296875,-0.315000000000000002220446049250313080847263336181640625) [-0.31500000|0.32000000] "rad" ADC
SG_ ARS_RDI_RCS_Clu_063 : 484|9@1+ (0.200000000000000011102230246251565404236316680908203125,-51.10000000000000142108547152020037174224853515625) [-51.10000000|51.10000000] "dBsm" ADC
SG_ ARS_RDI_SNR_Clu_063 : 493|7@1+ (0.5,0) [0E-008|63.50000000] "dB" ADC
SG_ ARS_RDI_DynProp_Clu_063 : 500|2@1+ (1,0) [0E-008|3.00000000] "unitless" ADC
SG_ ARS_RDI_Quality_Clu_063 : 502|2@1+ (1,0) [0E-008|3.00000000] "unitless" ADC

VAL_ 109 EPS_AgCtrlAvl 0 "Not available" 1 "Available" 2 "Reserved";
VAL_ 109 EPS_AgCtrlSts 0 "No active" 1 "Ready" 2 "active" 3 "ESA/AES Active";
VAL_ 109 EPS_TqCtrlAvl 0 "Not available" 1 "Available" 2 "Reserved";
VAL_ 109 EPS_TqCtrlSts 0 "No active" 1 "Ready" 2 "active" 3 "Reserved";
VAL_ 109 EPS_LdwWarnAvl 0 "Not available" 1 "Available";
VAL_ 109 EPS_LdwWarnSts 0 "NotActive" 1 "Active LevelA (high)" 2 "Active LevelB (low)";
VAL_ 109 EPS_SteerPinionAgVld 0 "Invalid" 1 "Valid";
VAL_ 109 EPS_SteerPinionAgRatVld 0 "Invalid" 1 "Valid";
VAL_ 109 EPS_SteerWheelAgVld 0 "Invalid" 1 "Valid";
VAL_ 109 EPS_SteerWheelAgRatVld 0 "Invalid" 1 "Valid";
VAL_ 109 EPS_AsscMotCrtTqVld 0 "Invalid" 1 "Valid";
VAL_ 109 EPS_DrvrSteerTqVld 0 "Invalid" 1 "Valid";
VAL_ 109 EPS_DrvrSteerTqFltVld 0 "Invalid" 1 "Valid";
VAL_ 109 EPS_SteerDrvrOvrd 0 "Not override" 1 "Override";
VAL_ 109 EPS_SteerDrvrOvrdVld 0 "Invalid" 1 "Valid";
VAL_ 109 EPS_ADCReqErrorFb 0 "No error" 1 "TqReq Invalid or Timeout" 2 "TqReq Out of Limit" 3 "AgReq Invalid or Timeout" 4 "AgSpdReq Out of Limit" 5 "AgReq Out of Limit" 6 "E2E error" 7 "other error";
VAL_ 109 EPS_AbortFb 0 "no Abnormal" 1 "Other Abnormal" 2 "driver interference StrWhl" 3 "ADC Request Abnormal" 4 "EPS Internal Failure" 5 "High Function Priority Intervene";
VAL_ 109 EPS_SteerMod 0 "Initial" 1 "Power steer" 2 "Angle control" 3 "Torque control" 4 "Torque control emergency" 5 "Failure";
VAL_ 109 EpsFltSts 0 "No failure" 1 "General failure" 2 "Critical failure" 3 "reserved";
VAL_ 109 EPS_BoostMod 0 "Standar Mode" 1 "Comfort Mode" 2 "Sport Mode" 3 "unknow";
VAL_ 109 EPS_TasCalSts 0 "Not Calibrated" 1 "Calibrated";
VAL_ 268 VehicleSpeed_Status 0 "Valid" 1 "Invalid";
VAL_ 268 WheelSpeed_FR_Status 0 "Valid" 1 "Invalid";
VAL_ 268 WheelSpeed_FL_Status 0 "Valid" 1 "Invalid";
VAL_ 268 WheelSpeed_RR_Status 0 "Valid" 1 "Invalid";
VAL_ 268 WheelSpeed_RL_Status 0 "Valid" 1 "Invalid";
VAL_ 268 RRWheelDriveDirection 0 "Invalid" 1 "Forward" 2 "Backward" 3 "Stop";
VAL_ 268 RLWheelDriveDirection 0 "Invalid" 1 "Forward" 2 "Backward" 3 "Stop";
VAL_ 268 FRWheelDriveDirection 0 "Invalid" 1 "Forward" 2 "Backward" 3 "Stop";
VAL_ 268 FLWheelDriveDirection 0 "Invalid" 1 "Forward" 2 "Backward" 3 "Stop";
VAL_ 268 FLWheelDriveDirectionStatus 0 "Valid" 1 "Invalid";
VAL_ 268 FRWheelDriveDirectionStatus 0 "Valid" 1 "Invalid";
VAL_ 268 RLWheelDriveDirectionStatus 0 "Valid" 1 "Invalid";
VAL_ 268 RRWheelDriveDirectionStatus 0 "Valid" 1 "Invalid";
VAL_ 268 RRWheelPulseCounterValidity 0 "Valid" 1 "Invalid";
VAL_ 268 RLWheelPulseCounterValidity 0 "Valid" 1 "Invalid";
VAL_ 268 FRWheelPulseCounterValidity 0 "Valid" 1 "Invalid";
VAL_ 268 FLWheelPulseCounterValidity 0 "Valid" 1 "Invalid";
VAL_ 268 EBD_Active 0 "NoActive" 1 "Active";
VAL_ 268 EBD_Fault 0 "NoFailure" 1 "Failure";
VAL_ 268 ABS_Active 0 "NoActive" 1 "Active";
VAL_ 268 ABS_Fault 0 "NoFailure" 1 "Failure";
VAL_ 268 VDC_Active 0 "NotActive" 1 "Active";
VAL_ 268 VDC_Fault 0 "NoFailure" 1 "Failure";
VAL_ 268 ESP_OFF 0 "ESPON" 1 "ESPOFF";
VAL_ 268 ESP_Active 0 "NoActive" 1 "Active";
VAL_ 268 TCS_Fault 0 "No Failure" 1 "Failure";
VAL_ 268 AVH_CtrlStatus 0 "AVHOff" 1 "AVHOnwithoutactivebraking" 2 "AVHOnwithactivebraking" 3 "AVHOnNoReady";
VAL_ 268 TCS_Active 0 "Not active" 1 "Active";
VAL_ 268 CCO_Active 0 "Not Active" 1 "Active" 2 "Standby" 3 "Fadeout";
VAL_ 268 HDC_CtrlStatus 0 "HDCOffNolamp" 1 "HDCOnwithoutactivebrakingLampon" 2 "HDCOnwithactivebrakingLampflashing" 3 "IPBwithoutHDC";
VAL_ 268 Yaw_Rate_Status 0 "NotValid" 1 "Valid";
VAL_ 268 AXstatus 0 "NotValid" 1 "Valid";
VAL_ 268 AYstatus 0 "NotValid" 1 "Valid";
VAL_ 268 AutomaticBrakingAvailable 0 "NotAvailable" 1 "Available";
VAL_ 268 AutomaticBrakingActive 0 "NoActive" 1 "Active";
VAL_ 268 IPB_InputRodStroke_Status 0 "Valid" 1 "Invalid";
VAL_ 268 FWA_warning 0 "NoFault" 1 "BrakingSystemOverTemperatureAlarmLevel1" 2 "BrakingSystemOverTemperatureAlarmLevel2" 3 "Reserved";
VAL_ 268 DiDyna_LDI_Active 0 "Not Active" 1 "Active";
VAL_ 268 Basc_FA 0 "Inactive" 1 "Active";
VAL_ 268 Basc_RA 0 "Inactive" 1 "Active";
VAL_ 268 AWBavailable 0 "No Active" 1 "Active";
VAL_ 268 AWBactive 0 "No Active" 1 "Active";
VAL_ 268 PrefillAvailable 0 "NotAvailable" 1 "Available";
VAL_ 268 PrefillActive 0 "NoActive" 1 "Active";
VAL_ 268 ESC_BrkTqCtrlAvlDriving 0 "not available" 1 "available";
VAL_ 268 ESC_BrkTqCtrlAvlParking 0 "not available" 1 "available" 2 "parking overspeed";
VAL_ 268 ESC_BrkTqCtrlActv 0 "NotActive" 1 "APA Active" 2 "ACCActive";
VAL_ 268 ESC_AebBrkTqAvl 0 "not available" 1 "available";
VAL_ 268 IPB_BRAKE_PEDAL_STARUS 0 "NotPressed" 1 "Pressed" 2 "Reserved" 3 "Error";
VAL_ 268 IPB_SimulatorPressure_Sts 0 "Valid" 1 "Invalid";
VAL_ 268 IPB_PlungerPressure_status 0 "Valid" 1 "Invalid";
VAL_ 268 DiDyna_LDI_Available 0 "Available" 1 "Not Available";
VAL_ 268 Ve_Target_Fdback_Tor_Flag_S 0 "NotIntialized" 1 "Normal active" 2 "Faulty" 3 "Normal passive";
VAL_ 268 IPB_BrakeOverride_val 0 "NotAvailable" 1 "Available";
VAL_ 268 IPB_BrakeOverride 0 "Inactive(default)" 1 "active";
VAL_ 268 HHC_Active 0 "No Active" 1 "Active";
VAL_ 268 ESC_AebBrkTqActv 0 "NotActive" 1 "Active";
VAL_ 268 VehicleStandstill 0 "not standstill" 1 "standstill";
VAL_ 268 BMsr_FA_S 0 "Not active" 1 "Active";
VAL_ 268 BMsr_RA_S 0 "Not active" 1 "Active";
VAL_ 90 VCU_ActPedlPosnVld 0 "Invalid" 1 "Valid";
VAL_ 90 VCU_AccrPedlPosnVld 0 "Invalid" 1 "Valid";
VAL_ 90 VCU_DrvrAccrPedlOvrd 0 "Not Super Drive" 1 "Super Drive";
VAL_ 90 VCU_DrvrAccrPedlOvrdVLD 0 "Invalid" 1 "Valid";
VAL_ 90 VCU_VehWhlActTqVld 0 "Invalid" 1 "Valid";
VAL_ 90 VCU_FrntWhlReqTqVld 0 "Invalid" 1 "Valid";
VAL_ 90 VCU_ReWhlReqTqVld 0 "Invalid" 1 "Valid";
VAL_ 90 VCU_VehWhlReqTqVld 0 "Invalid" 1 "Valid";
VAL_ 90 VCU_PtRgnTqMaxVld 0 "Invalid" 1 "Valid";
VAL_ 90 VCU_PtElecTqMaxVld 0 "Invalid" 1 "Valid";
VAL_ 90 VCU_MotorRegenTrqLmtInDValid 0 "Invalid" 1 "Valid";
VAL_ 90 VCU_PtTqAvl 0 "Unavailable" 1 "Available" 2 "Degradation available" 3 "reserved";
VAL_ 90 VCU_PtTqActvSts 0 "No activation" 1 "Activation";
VAL_ 90 VCU_MCUModActvSt 0 "Torque mode" 1 "RPM mode" 2 "SV mode" 3 "reserved";
VAL_ 90 VCU_MCUBlkSt 0 "No block" 1 "block" 2 "reserved";
VAL_ 90 VCU_SpdSvModAvl 0 "Not available" 1 "Available";
VAL_ 90 VCU_MCUStandstill 0 "not standstill" 1 "standstill";
VAL_ 90 VCU_MCUSpdSVModFlt 0 "No fault" 1 "Torque absolute value too large fault";
VAL_ 90 VCU_ErrorFb 0 "No error" 1 "ADC req flag invalid" 2 "High voltag error" 3 "MCU error" 4 "BMS error" 5 "No response to ADC";
VAL_ 90 Rnk_efc_flg_hw 0 "valid" 1 "invalid";
VAL_ 90 Rnk_hw 0 "Reserved" 1 "P" 2 "R" 3 "N" 4 "D";
VAL_ 90 F_mot_spd_err_flg_hw 0 "NoError" 1 "Error";
VAL_ 90 R_mot_spd_err_hw 0 "NoError" 1 "Error";
VAL_ 90 Faxis_act_tq_efc_flg_hw 0 "nofailure" 1 "failure";
VAL_ 90 R_mot_fac_tq_sts_hw 0 "nofailure" 1 "failure";
VAL_ 90 Act_drv_mod_hw 0 "Invalid" 1 "NORMAL" 2 "ECO" 3 "SPORT" 4 "SnowIceGrassGravel" 5 "Sand" 6 "MudRuts" 7 "Mountain" 8 "Rock" 9 "Wading" 10 "FloatingWater" 11 "ATFS" 12 "UTurnInPlace" 13 "reserved" 14 "ECO+" 15 "reserved" 16 "reserved" 17 "DakarModePullMode" 18 "LimpModeReserved" 19 "CustomMode" 20 "SPORT+" 21 "AutomaticMode" 22 "TrackMode" 23 "MaxTraction" 24 "reserved" 25 "Terrainassistantmode" 26 "GetOffTheGround" 27 "CreepingMode" 28 "AgileSteering" 29 "DriftMode" 30 "DragRace" 31 "TrackRace" 32 "Individual" 33 "AutoDriftTechnologyADT" 34 "FlexibleSteering" 35 "CompassTurn" 36 "Trackmode" 37 "DragAndDropMode" 38 "DeepSnow" 39 "VSW" 40 "DiDynaDCW" 41 "TireBurstSystem" 42 "ExtremeMoose" 43 "SnowChainMode";
VAL_ 90 Ok_lamp_hw 0 "Nodisplay" 1 "OK" 2 "disgOK" 3 "reserve";
VAL_ 90 VCU_DriveReady 0 "Nodt ready" 1 "ready" 2 "reserved" 3 "reserved";
VAL_ 90 Bsg_Gmcu_start_eng_sts 0 "Invalid" 1 "Succed" 2 "Failed" 3 "Engine starting process";
VAL_ 90 VCU_REQ_ADAS_SPC_FUN_STOP_EN_S 0 "no request" 1 "request" 2 "reserved" 3 "invalid";
VAL_ 90 FL_mot_whl_act_tq_efc_flg_S 0 "valid" 1 "invalid";
VAL_ 90 FR_mot_whl_act_tq_efc_flg_S 0 "valid" 1 "invalid";
VAL_ 90 LR_mot_whl_act_tq_efc_flg_S 0 "valid" 1 "invalid";
VAL_ 90 RR_mot_whl_act_tq_efc_flg_S 0 "valid" 1 "invalid";
VAL_ 90 FL_mot_spd_efc_flg_S 0 "valid" 1 "invalid";
VAL_ 90 FR_mot_spd_efc_flg_S 0 "valid" 1 "invalid";
VAL_ 90 RL_mot_spd_efc_flg_S 0 "valid" 1 "invalid";
VAL_ 90 RR_mot_spd_efc_flg_S 0 "valid" 1 "invalid";
VAL_ 90 AI_Drift_Control_Mode_Response_State_S 0 "Normal response" 1 "no response";
VAL_ 90 E4_ParkEPS_Contrl_Learning_S 0 "reserved" 1 "VCU Control" 2 "ADAS Control" 3 "invalid";
VAL_ 860 Gear_System_Status_S 0 "Normal" 1 "Abnormal";
VAL_ 860 SCU_Feedback_APA_Status_Info_S 0 "NooperationIsNotCtrlled" 1 "NormalOperationNormalCtrl" 2 "DriveGearIntrfDriverIntrGearCtrl" 3 "Reserved";
VAL_ 860 Gear_Recognize_Status_S 0 "InitialNoGearShifting" 1 "P" 2 "R" 3 "N" 4 "D" 5 "M" 6 "Positive" 7 "Negative";
VAL_ 860 Gear_Shift_Req 0 "Initial" 1 "P" 2 "R" 3 "N" 4 "D";
VAL_ 860 Park_Button_Status_S 0 "ButtonOFF" 1 "ButtonON" 2 "ButtonStuck" 3 "ButtonOpen" 4 "Buttonshot" 5 "ButtonOutofRange";
VAL_ 813 Obj_Valid_S 0 "NoObject" 1 "TargetObjectDetected";
VAL_ 813 Tau_Gap_Set_S 0 "TauGap0" 1 "TauGap1" 2 "TauGap2" 3 "TauGap3" 4 "TauGap4" 5 "TauGap5" 6 "TauGap6" 7 "TauGap7";
VAL_ 813 Dx_Tar_Obj_S 0 "Distance0" 1 "Distance1" 2 "Distance2" 3 "Distance3" 4 "Distance4" 5 "Distance5" 6 "Distance6" 7 "Distance7";
VAL_ 813 PCW_Pre_Warning_S 0 "NoWarning" 1 "Warning";
VAL_ 813 PCW_Latent_Warning_S 0 "NoWarning" 1 "Warning";
VAL_ 813 PCW_State_S 0 "OFF" 1 "ON";
VAL_ 813 ACC_Mode_Display_S 0 "OFFMode" 1 "PassiveMode" 2 "StandByMode" 3 "ActiveControlMode" 4 "BrakeOnlyMode" 5 "Override" 6 "Reserved" 7 "FailureMode";
VAL_ 813 ACC_State_S 0 "OFF" 1 "ON";
VAL_ 813 Take_Over_Req_S 0 "NoTakeOverrequest" 1 "ValidTakeOverreques";
VAL_ 813 Speed_Unit_Set_S2 0 "Invalid" 1 "KmH" 2 "MPH" 3 "Reserved";
VAL_ 813 CCR_AEB_Error_S 0 "NoDisplayNodisplay" 1 "PleaseCheckAEBSystem";
VAL_ 813 ACC_Text_Info_For_Driver_S 0 "NoDisplay" 1 "ACCCannotBeActivated" 2 "ACCCanceled" 3 "ACCIsActivated" 4 "OvertakingAcceleration" 5 "DangerPleaseBrake" 6 "PayAttentionTotheSurrounding" 7 "ACCIsOpen" 8 "ACCIsClosed" 9 "PleaseCheckAdaptiveCruiseSystem" 10 "PleaseConfirmIfSeatBeltIsFastened" 11 "PleaseConfirmIfTheDoorIsClosed" 12 "PleaseConfirmIfTheGearIsInDGear" 13 "PleaseConfirmIfEPBIsReleased" 14 "PleaseConfirmIfESPIsEnabled" 15 "ACC_StopGo" 16 "UnableToActivInCurDriveMode" 17 "ActiveADCFlickEitherPickTwice" 18 "Slightly avoiding，will resume center later" 19 "ADC forbidden during this driving cycle" 20 "pleasereleasingofbrake" 21 "LCCCannotBeActivated" 22 "Assistedisabouttoexit" 23 "ACCPassiveexit" 24 "Setspeedtolimit" 25 "LCCactivetoACC" 26 "LCCpassivetoACC" 27 "ILCAspeednotmet" 28 "PleaseactivePilotfirst" 29 "ADAS forbidden during this driving cycle" 30 "ADSCannotBeActivated" 31 "Reserved";
VAL_ 813 CCR_FCW_Error_S 0 "NoDisplayNodisplay" 1 "PleaseCheckTheFCWSystem";
VAL_ 813 Pedestrian_FCW_Brak_Error_S 0 "NoDisplayNodisplay" 1 "PleaseCheckTheVRUSystem";
VAL_ 813 Acute_Warning_S 0 "NoWarning" 1 "Warning";
VAL_ 813 AEB_State_S 0 "OFF" 1 "ON";
VAL_ 813 PCWLevelState 0 "OFF" 1 "Level1Low" 2 "InLevel2SelectedByDefault" 3 "Level3High";
VAL_ 813 Front_radar_FCTB_Warning 0 "not_warning" 1 "AEB warning" 2 "FCTB warning _left" 3 "FCTB warning _right" 4 "FCTB warning_left_right";
VAL_ 813 ACC_Mode_Display1_S 0 "OFFMode" 1 "PassiveMode" 2 "StandByMode" 3 "ActiveControlMode" 4 "BrakeOnlyMode" 5 "Override" 6 "StandStillActiveMode" 7 "StandStillWaitMode" 8 "Temporary Failure mode" 9 "permanent failure";
VAL_ 813 ELK_Assemble_Status_S 0 "NO" 1 "YES";
VAL_ 813 MRR_Modulation_Status 0 "No Failure" 1 "TimesyncFailure_ModFail" 2 "TimesyncCorrect_ModFail" 3 "Reserved";
VAL_ 814 ACC_Drive_Off_Req_S_32E 0 "Norequest" 1 "Request";
VAL_ 814 ACC_DecTo_Stop_Req_S_32E 0 "Norequest" 1 "Request";
VAL_ 814 ACC_Minimum_Braking_S_32E 0 "Nodemand" 1 "Demand";
VAL_ 814 Brake_Preferred_S_32E 0 "Nodemand" 1 "Demand";
VAL_ 814 ACC_Mode_S_32E 0 "OFF" 1 "Passivemode" 2 "StandBymode" 3 "ActiveControlmode" 4 "BrakeOnlymode" 5 "Override" 6 "Standstill" 7 "Failuremode";
VAL_ 814 ESP_VLC_Shut_Down_Request_S_32E 0 "Softoff" 1 "Fastoff" 2 "Immediateoff" 3 "Initial";
VAL_ 814 LSM_Request_Status_S_32E 0 "none" 1 "NRP" 2 "TBA";
VAL_ 482 ADC_AngleReq_St_S 0 "Inhibited" 1 "Ready" 2 "Active" 3 "Reserved";
VAL_ 482 ADC2SCU_P_Req 0 "initial" 1 "P_request" 2 "Reserved" 3 "Reserved";
VAL_ 482 SuspInhibitReq1E2_S 0 "No Request" 1 "APA Request" 2 "RPA Request" 3 "HPA Request" 4 "AVP Request" 5 "MEB Request" 6 "Reserved" 7 "Reserved";
VAL_ 482 SuspInhibitReq1E2_Valid_S 0 "Valid" 1 "Invalid";
VAL_ 790 HMA_Stats_S_316 0 "Off" 1 "Passive" 2 "Tandby" 3 "Active" 4 "Fault" 5 "CameraBlocked";
VAL_ 790 HMA_High_Beam_Request_S_316 0 "LowBeamRequest" 1 "HighBeamRequest";
VAL_ 790 Left_Line_Tracking_Status_S 0 "NoDisplay" 1 "LineTracking" 2 "Intervention" 3 "Warning";
VAL_ 790 Lane_Assistant_Mode_Status_S 0 "Disable" 1 "LaneDeparture" 2 "LKS/LDP" 3 "FullFunction";
VAL_ 790 LKS_Sensitivity_S 0 "LowSensitivity" 1 "HighSensitivity" 2 "Reserved" 3 "Reserved";
VAL_ 790 LDP_LDW_Camera_Blocked_S 0 "Normal" 1 "CameraBlocked";
VAL_ 790 LDP_Fault_S 0 "Normal" 1 "LKSFault";
VAL_ 790 LDW_fault1_S 0 "Normal" 1 "LDWFault";
VAL_ 790 ACC_AEB_Camera_Blocked_Infro_S 0 "NoDisplay" 1 "ACCAEBCameraBlock";
VAL_ 790 Over_Temperature 0 "OverTemp" 1 "Normal";
VAL_ 790 LKS_torque_request_staus_S 0 "Inhibited" 1 "Ready" 2 "Active" 3 "Reserved";
VAL_ 790 LDP_New_Take_Over_Req_S 0 "Invalid" 1 "Warning Level1" 2 "Warning Level2" 3 "Warning Level3" 4 "Warning Level4";
VAL_ 790 RSF_Output_Speed_Limit_Unit_S 0 "Unknown" 1 "KMH" 2 "MPH" 3 "Reserved";
VAL_ 790 Right_Line_Tracking_Stats_S 0 "NoDisplay" 1 "LineTracking" 2 "Intervention" 3 "Warning";
VAL_ 790 TJA_ICA_function_status_S 0 "OFF" 1 "Passive" 2 "Active1" 3 "Active2" 4 "Fault" 5 "StandBy";
VAL_ 790 ALL_Function_Camera_Bloc_Infro_S 0 "NoDisplay" 1 "ALLFunctionCameraBlock";
VAL_ 790 RSF_Output_Speed_Limit_S 0 "NoDisplay" 1 "SPLCancelled" 2 "SPL5" 3 "SPL10" 4 "SPL15" 5 "SPL20" 6 "SPL25";
VAL_ 790 LDW_Warning_Mode_Stats_S 0 "VibrationOnly" 1 "SoundOnly" 2 "VibrationSound" 3 "Reserved";
VAL_ 790 ADC_Take_Over_Req1_S 0 "Inactive" 1 "WarningLevel1" 2 "WarningLevel2" 3 "WarningLevel3";
VAL_ 834 VCU_Acelrogra_Dpth_Virtual_Val_S 0 "Invalid" 1 "Valid";
VAL_ 834 VCU_Brake_Depth_Virtual_Value_S 0 "Invalid" 1 "Valid";
VAL_ 834 VCU_Vehicle_Run_Mode_S 0 "Reserved" 1 "EconomicMode" 2 "SportsMode" 3 "snowmode_EVorNormalModeNormal_DM";
VAL_ 834 VCU_Vehicle_Run_Mode_S2 0 "Reserved_EVorNotSwitched_DM" 1 "Normal_EVorSwitching_DM" 2 "Reserved" 3 "Reserved";
VAL_ 834 VCU_Goal_Gear_S 0 "Reserved" 1 "PGear" 2 "RGea" 3 "NGea" 4 "DGea" 5 "Reserved" 6 "Reserved" 7 "Reserved" 8 "Reserved" 9 "Reserved" 10 "Reserved" 11 "Reserved" 12 "Reserved" 13 "Reserved" 14 "Reserved" 15 "Reserved";
VAL_ 834 Ins_disp_veh_work_mod 0 "stop" 1 "EV" 2 "max EV" 3 "HEV";
VAL_ 834 Tar_road_mod 0 "Invalid" 1 "Non-topographic model" 2 "GrassGravelGroundSnow" 3 "MuddyGroundRutGround" 4 "Sand" 5 "Mountain" 6 "Rock" 7 "Reserved";
VAL_ 834 Act_road_mod 0 "Invalid" 1 "Non-topographic model" 2 "GrassGravelGroundSnow" 3 "MuddyGroundRutGround" 4 "Sand";
VAL_ 944 SWS_Dist_Set_S 0 "FirstGear1s" 1 "SecondGear15s" 2 "ThirdGear19s" 3 "FourthGear23s" 4 "Invalid";
VAL_ 944 SWS_Speed_Set_S 0 "InitialPosition" 1 "DecelerateFirstGear" 2 "DecelerateSecondGear" 3 "AccelerateFirstGear" 4 "AccelerateSecondGear";
VAL_ 944 Dipilot_Switch_Signal_S 0 "Invalid" 1 "SwitchPress";
VAL_ 944 SWS_Cruise_Or_Speed_Limit_Mode_S 0 "SpeedLimitMode（reserved）OFF" 1 "CruiseMode";
VAL_ 944 SWS_Reset_Signal_S 0 "InitialPosition" 1 "ResetAction";
VAL_ 944 SWS_Cruis_Swch_Fault_Stat_flg_S 0 "Invalid" 1 "Normal";
VAL_ 944 SWS_Set_Signal_S 0 "Invalid" 1 "SETSwitchIsPressed";
VAL_ 944 SWS_Dist_Switch_Signal_Down_S 0 "Invalid" 1 "DistanceSwitchIsPressed";
VAL_ 944 SWS_Dist_Switch_Signal_Up_S 0 "Invalid" 1 "DistanceSwitchPlusPress";
VAL_ 944 Cruise_Switch_Operation_Mode_S 0 "CruiseButtonOnSteeringWheel" 1 "NoCruiseButton";
VAL_ 944 ACC_Switch_Signal_S 0 "Invalid" 1 "SwitchPress";
VAL_ 944 HOD_System_Status_S 0 "Available" 1 "InitialStatus" 2 "Fault" 3 "Not Calibration";
VAL_ 944 Driver_Grip_S 0 "invalid" 1 "NoHandDetected" 2 "Hand Detected";
VAL_ 944 Driver_Grip_Area_S 0 "NoHand" 1 "LeftHalfArea" 2 "RightHalfArea";
VAL_ 944 Driver_SingleHands_State_S 0 "NoHandsOn" 1 "One Hand" 2 "Both HandsOn";
VAL_ 944 Left_Paddle_For_Advanced_Driving_Functions_S 0 "Invalid" 1 "LeftPaddlePressed" 2 "LongPressOnTheLeftPaddle" 3 "Reserved";
VAL_ 944 Right_Paddle_For_Advanced_Driving_Functions_S 0 "Invalid" 1 "RightPaddlePressed" 2 "LongPressOnTheRightPaddle" 3 "Reserved";
VAL_ 944 APA 0 "Invalid" 1 "PressValid";
VAL_ 944 Road_Speed_Limit_Seting_S 0 "Invalid" 1 "PressValid";
VAL_ 944 Vehicle_Distance_button_Flag_S 0 "Invalid" 1 "Nodistance+Button";
VAL_ 1646 ARS_OD_TaskValidFlag 0 "INVALID" 1 "VALID";
VAL_ 1646 ARS_OD_ExtendedCycleFlag 0 "FALSE" 1 "TRUE";
VAL_ 1646 ARS_OD_TimesynSts 1 "TIMEOUT" 2 "Reserved1" 4 "SYNC_TO_GATEWAY" 8 "GLOBAL_TIME_BASE" 16 "TIMELEAP_FUTURE" 32 "TIMELEAP_PAST" 64 "Reserved6" 128 "Extension GENERAL_ERROR";
VAL_ 1600 ARS_RDI_DynProp_Clu_000 0 "STATIONARY" 1 "MOVING" 2 "AMBIGUIOUS" 3 "RESERVED";
VAL_ 1600 ARS_RDI_Quality_Clu_000 0 "INVALID" 1 "LOW" 2 "MID" 3 "HIGH";
VAL_ 1600 ARS_RDI_DynProp_Clu_001 0 "STATIONARY" 1 "MOVING" 2 "AMBIGUIOUS" 3 "RESERVED";
VAL_ 1600 ARS_RDI_Quality_Clu_001 0 "INVALID" 1 "LOW" 2 "MID" 3 "HIGH";
VAL_ 1600 ARS_RDI_DynProp_Clu_002 0 "STATIONARY" 1 "MOVING" 2 "AMBIGUIOUS" 3 "RESERVED";
VAL_ 1600 ARS_RDI_Quality_Clu_002 0 "INVALID" 1 "LOW" 2 "MID" 3 "HIGH";
VAL_ 1600 ARS_RDI_DynProp_Clu_003 0 "STATIONARY" 1 "MOVING" 2 "AMBIGUIOUS" 3 "RESERVED";
VAL_ 1600 ARS_RDI_Quality_Clu_003 0 "INVALID" 1 "LOW" 2 "MID" 3 "HIGH";
VAL_ 1600 ARS_RDI_DynProp_Clu_004 0 "STATIONARY" 1 "MOVING" 2 "AMBIGUIOUS" 3 "RESERVED";
VAL_ 1600 ARS_RDI_Quality_Clu_004 0 "INVALID" 1 "LOW" 2 "MID" 3 "HIGH";
VAL_ 1600 ARS_RDI_DynProp_Clu_005 0 "STATIONARY" 1 "MOVING" 2 "AMBIGUIOUS" 3 "RESERVED";
VAL_ 1600 ARS_RDI_Quality_Clu_005 0 "INVALID" 1 "LOW" 2 "MID" 3 "HIGH";
VAL_ 1600 ARS_RDI_DynProp_Clu_006 0 "STATIONARY" 1 "MOVING" 2 "AMBIGUIOUS" 3 "RESERVED";
VAL_ 1600 ARS_RDI_Quality_Clu_006 0 "INVALID" 1 "LOW" 2 "MID" 3 "HIGH";
VAL_ 1600 ARS_RDI_DynProp_Clu_007 0 "STATIONARY" 1 "MOVING" 2 "AMBIGUIOUS" 3 "RESERVED";
VAL_ 1600 ARS_RDI_Quality_Clu_007 0 "INVALID" 1 "LOW" 2 "MID" 3 "HIGH";
VAL_ 1601 ARS_RDI_DynProp_Clu_008 0 "STATIONARY" 1 "MOVING" 2 "AMBIGUIOUS" 3 "RESERVED";
VAL_ 1601 ARS_RDI_Quality_Clu_008 0 "INVALID" 1 "LOW" 2 "MID" 3 "HIGH";
VAL_ 1601 ARS_RDI_DynProp_Clu_009 0 "STATIONARY" 1 "MOVING" 2 "AMBIGUIOUS" 3 "RESERVED";
VAL_ 1601 ARS_RDI_Quality_Clu_009 0 "INVALID" 1 "LOW" 2 "MID" 3 "HIGH";
VAL_ 1601 ARS_RDI_DynProp_Clu_010 0 "STATIONARY" 1 "MOVING" 2 "AMBIGUIOUS" 3 "RESERVED";
VAL_ 1601 ARS_RDI_Quality_Clu_010 0 "INVALID" 1 "LOW" 2 "MID" 3 "HIGH";
VAL_ 1601 ARS_RDI_DynProp_Clu_011 0 "STATIONARY" 1 "MOVING" 2 "AMBIGUIOUS" 3 "RESERVED";
VAL_ 1601 ARS_RDI_Quality_Clu_011 0 "INVALID" 1 "LOW" 2 "MID" 3 "HIGH";
VAL_ 1601 ARS_RDI_DynProp_Clu_012 0 "STATIONARY" 1 "MOVING" 2 "AMBIGUIOUS" 3 "RESERVED";
VAL_ 1601 ARS_RDI_Quality_Clu_012 0 "INVALID" 1 "LOW" 2 "MID" 3 "HIGH";
VAL_ 1601 ARS_RDI_DynProp_Clu_013 0 "STATIONARY" 1 "MOVING" 2 "AMBIGUIOUS" 3 "RESERVED";
VAL_ 1601 ARS_RDI_Quality_Clu_013 0 "INVALID" 1 "LOW" 2 "MID" 3 "HIGH";
VAL_ 1601 ARS_RDI_DynProp_Clu_014 0 "STATIONARY" 1 "MOVING" 2 "AMBIGUIOUS" 3 "RESERVED";
VAL_ 1601 ARS_RDI_Quality_Clu_014 0 "INVALID" 1 "LOW" 2 "MID" 3 "HIGH";
VAL_ 1601 ARS_RDI_DynProp_Clu_015 0 "STATIONARY" 1 "MOVING" 2 "AMBIGUIOUS" 3 "RESERVED";
VAL_ 1601 ARS_RDI_Quality_Clu_015 0 "INVALID" 1 "LOW" 2 "MID" 3 "HIGH";
VAL_ 1602 ARS_RDI_DynProp_Clu_016 0 "STATIONARY" 1 "MOVING" 2 "AMBIGUIOUS" 3 "RESERVED";
VAL_ 1602 ARS_RDI_Quality_Clu_016 0 "INVALID" 1 "LOW" 2 "MID" 3 "HIGH";
VAL_ 1602 ARS_RDI_DynProp_Clu_017 0 "STATIONARY" 1 "MOVING" 2 "AMBIGUIOUS" 3 "RESERVED";
VAL_ 1602 ARS_RDI_Quality_Clu_017 0 "INVALID" 1 "LOW" 2 "MID" 3 "HIGH";
VAL_ 1602 ARS_RDI_DynProp_Clu_018 0 "STATIONARY" 1 "MOVING" 2 "AMBIGUIOUS" 3 "RESERVED";
VAL_ 1602 ARS_RDI_Quality_Clu_018 0 "INVALID" 1 "LOW" 2 "MID" 3 "HIGH";
VAL_ 1602 ARS_RDI_DynProp_Clu_019 0 "STATIONARY" 1 "MOVING" 2 "AMBIGUIOUS" 3 "RESERVED";
VAL_ 1602 ARS_RDI_Quality_Clu_019 0 "INVALID" 1 "LOW" 2 "MID" 3 "HIGH";
VAL_ 1602 ARS_RDI_DynProp_Clu_020 0 "STATIONARY" 1 "MOVING" 2 "AMBIGUIOUS" 3 "RESERVED";
VAL_ 1602 ARS_RDI_Quality_Clu_020 0 "INVALID" 1 "LOW" 2 "MID" 3 "HIGH";
VAL_ 1602 ARS_RDI_DynProp_Clu_021 0 "STATIONARY" 1 "MOVING" 2 "AMBIGUIOUS" 3 "RESERVED";
VAL_ 1602 ARS_RDI_Quality_Clu_021 0 "INVALID" 1 "LOW" 2 "MID" 3 "HIGH";
VAL_ 1602 ARS_RDI_DynProp_Clu_022 0 "STATIONARY" 1 "MOVING" 2 "AMBIGUIOUS" 3 "RESERVED";
VAL_ 1602 ARS_RDI_Quality_Clu_022 0 "INVALID" 1 "LOW" 2 "MID" 3 "HIGH";
VAL_ 1602 ARS_RDI_DynProp_Clu_023 0 "STATIONARY" 1 "MOVING" 2 "AMBIGUIOUS" 3 "RESERVED";
VAL_ 1602 ARS_RDI_Quality_Clu_023 0 "INVALID" 1 "LOW" 2 "MID" 3 "HIGH";
VAL_ 1603 ARS_RDI_DynProp_Clu_024 0 "STATIONARY" 1 "MOVING" 2 "AMBIGUIOUS" 3 "RESERVED";
VAL_ 1603 ARS_RDI_Quality_Clu_024 0 "INVALID" 1 "LOW" 2 "MID" 3 "HIGH";
VAL_ 1603 ARS_RDI_DynProp_Clu_025 0 "STATIONARY" 1 "MOVING" 2 "AMBIGUIOUS" 3 "RESERVED";
VAL_ 1603 ARS_RDI_Quality_Clu_025 0 "INVALID" 1 "LOW" 2 "MID" 3 "HIGH";
VAL_ 1603 ARS_RDI_DynProp_Clu_026 0 "STATIONARY" 1 "MOVING" 2 "AMBIGUIOUS" 3 "RESERVED";
VAL_ 1603 ARS_RDI_Quality_Clu_026 0 "INVALID" 1 "LOW" 2 "MID" 3 "HIGH";
VAL_ 1603 ARS_RDI_DynProp_Clu_027 0 "STATIONARY" 1 "MOVING" 2 "AMBIGUIOUS" 3 "RESERVED";
VAL_ 1603 ARS_RDI_Quality_Clu_027 0 "INVALID" 1 "LOW" 2 "MID" 3 "HIGH";
VAL_ 1603 ARS_RDI_DynProp_Clu_028 0 "STATIONARY" 1 "MOVING" 2 "AMBIGUIOUS" 3 "RESERVED";
VAL_ 1603 ARS_RDI_Quality_Clu_028 0 "INVALID" 1 "LOW" 2 "MID" 3 "HIGH";
VAL_ 1603 ARS_RDI_DynProp_Clu_029 0 "STATIONARY" 1 "MOVING" 2 "AMBIGUIOUS" 3 "RESERVED";
VAL_ 1603 ARS_RDI_Quality_Clu_029 0 "INVALID" 1 "LOW" 2 "MID" 3 "HIGH";
VAL_ 1603 ARS_RDI_DynProp_Clu_030 0 "STATIONARY" 1 "MOVING" 2 "AMBIGUIOUS" 3 "RESERVED";
VAL_ 1603 ARS_RDI_Quality_Clu_030 0 "INVALID" 1 "LOW" 2 "MID" 3 "HIGH";
VAL_ 1603 ARS_RDI_DynProp_Clu_031 0 "STATIONARY" 1 "MOVING" 2 "AMBIGUIOUS" 3 "RESERVED";
VAL_ 1603 ARS_RDI_Quality_Clu_031 0 "INVALID" 1 "LOW" 2 "MID" 3 "HIGH";
VAL_ 1604 ARS_RDI_DynProp_Clu_032 0 "STATIONARY" 1 "MOVING" 2 "AMBIGUIOUS" 3 "RESERVED";
VAL_ 1604 ARS_RDI_Quality_Clu_032 0 "INVALID" 1 "LOW" 2 "MID" 3 "HIGH";
VAL_ 1604 ARS_RDI_DynProp_Clu_033 0 "STATIONARY" 1 "MOVING" 2 "AMBIGUIOUS" 3 "RESERVED";
VAL_ 1604 ARS_RDI_Quality_Clu_033 0 "INVALID" 1 "LOW" 2 "MID" 3 "HIGH";
VAL_ 1604 ARS_RDI_DynProp_Clu_034 0 "STATIONARY" 1 "MOVING" 2 "AMBIGUIOUS" 3 "RESERVED";
VAL_ 1604 ARS_RDI_Quality_Clu_034 0 "INVALID" 1 "LOW" 2 "MID" 3 "HIGH";
VAL_ 1604 ARS_RDI_DynProp_Clu_035 0 "STATIONARY" 1 "MOVING" 2 "AMBIGUIOUS" 3 "RESERVED";
VAL_ 1604 ARS_RDI_Quality_Clu_035 0 "INVALID" 1 "LOW" 2 "MID" 3 "HIGH";
VAL_ 1604 ARS_RDI_DynProp_Clu_036 0 "STATIONARY" 1 "MOVING" 2 "AMBIGUIOUS" 3 "RESERVED";
VAL_ 1604 ARS_RDI_Quality_Clu_036 0 "INVALID" 1 "LOW" 2 "MID" 3 "HIGH";
VAL_ 1604 ARS_RDI_DynProp_Clu_037 0 "STATIONARY" 1 "MOVING" 2 "AMBIGUIOUS" 3 "RESERVED";
VAL_ 1604 ARS_RDI_Quality_Clu_037 0 "INVALID" 1 "LOW" 2 "MID" 3 "HIGH";
VAL_ 1604 ARS_RDI_DynProp_Clu_038 0 "STATIONARY" 1 "MOVING" 2 "AMBIGUIOUS" 3 "RESERVED";
VAL_ 1604 ARS_RDI_Quality_Clu_038 0 "INVALID" 1 "LOW" 2 "MID" 3 "HIGH";
VAL_ 1604 ARS_RDI_DynProp_Clu_039 0 "STATIONARY" 1 "MOVING" 2 "AMBIGUIOUS" 3 "RESERVED";
VAL_ 1604 ARS_RDI_Quality_Clu_039 0 "INVALID" 1 "LOW" 2 "MID" 3 "HIGH";
VAL_ 1605 ARS_RDI_DynProp_Clu_040 0 "STATIONARY" 1 "MOVING" 2 "AMBIGUIOUS" 3 "RESERVED";
VAL_ 1605 ARS_RDI_Quality_Clu_040 0 "INVALID" 1 "LOW" 2 "MID" 3 "HIGH";
VAL_ 1605 ARS_RDI_DynProp_Clu_041 0 "STATIONARY" 1 "MOVING" 2 "AMBIGUIOUS" 3 "RESERVED";
VAL_ 1605 ARS_RDI_Quality_Clu_041 0 "INVALID" 1 "LOW" 2 "MID" 3 "HIGH";
VAL_ 1605 ARS_RDI_DynProp_Clu_042 0 "STATIONARY" 1 "MOVING" 2 "AMBIGUIOUS" 3 "RESERVED";
VAL_ 1605 ARS_RDI_Quality_Clu_042 0 "INVALID" 1 "LOW" 2 "MID" 3 "HIGH";
VAL_ 1605 ARS_RDI_DynProp_Clu_043 0 "STATIONARY" 1 "MOVING" 2 "AMBIGUIOUS" 3 "RESERVED";
VAL_ 1605 ARS_RDI_Quality_Clu_043 0 "INVALID" 1 "LOW" 2 "MID" 3 "HIGH";
VAL_ 1605 ARS_RDI_DynProp_Clu_044 0 "STATIONARY" 1 "MOVING" 2 "AMBIGUIOUS" 3 "RESERVED";
VAL_ 1605 ARS_RDI_Quality_Clu_044 0 "INVALID" 1 "LOW" 2 "MID" 3 "HIGH";
VAL_ 1605 ARS_RDI_DynProp_Clu_045 0 "STATIONARY" 1 "MOVING" 2 "AMBIGUIOUS" 3 "RESERVED";
VAL_ 1605 ARS_RDI_Quality_Clu_045 0 "INVALID" 1 "LOW" 2 "MID" 3 "HIGH";
VAL_ 1605 ARS_RDI_DynProp_Clu_046 0 "STATIONARY" 1 "MOVING" 2 "AMBIGUIOUS" 3 "RESERVED";
VAL_ 1605 ARS_RDI_Quality_Clu_046 0 "INVALID" 1 "LOW" 2 "MID" 3 "HIGH";
VAL_ 1605 ARS_RDI_DynProp_Clu_047 0 "STATIONARY" 1 "MOVING" 2 "AMBIGUIOUS" 3 "RESERVED";
VAL_ 1605 ARS_RDI_Quality_Clu_047 0 "INVALID" 1 "LOW" 2 "MID" 3 "HIGH";
VAL_ 1606 ARS_RDI_DynProp_Clu_048 0 "STATIONARY" 1 "MOVING" 2 "AMBIGUIOUS" 3 "RESERVED";
VAL_ 1606 ARS_RDI_Quality_Clu_048 0 "INVALID" 1 "LOW" 2 "MID" 3 "HIGH";
VAL_ 1606 ARS_RDI_DynProp_Clu_049 0 "STATIONARY" 1 "MOVING" 2 "AMBIGUIOUS" 3 "RESERVED";
VAL_ 1606 ARS_RDI_Quality_Clu_049 0 "INVALID" 1 "LOW" 2 "MID" 3 "HIGH";
VAL_ 1606 ARS_RDI_DynProp_Clu_050 0 "STATIONARY" 1 "MOVING" 2 "AMBIGUIOUS" 3 "RESERVED";
VAL_ 1606 ARS_RDI_Quality_Clu_050 0 "INVALID" 1 "LOW" 2 "MID" 3 "HIGH";
VAL_ 1606 ARS_RDI_DynProp_Clu_051 0 "STATIONARY" 1 "MOVING" 2 "AMBIGUIOUS" 3 "RESERVED";
VAL_ 1606 ARS_RDI_Quality_Clu_051 0 "INVALID" 1 "LOW" 2 "MID" 3 "HIGH";
VAL_ 1606 ARS_RDI_DynProp_Clu_052 0 "STATIONARY" 1 "MOVING" 2 "AMBIGUIOUS" 3 "RESERVED";
VAL_ 1606 ARS_RDI_Quality_Clu_052 0 "INVALID" 1 "LOW" 2 "MID" 3 "HIGH";
VAL_ 1606 ARS_RDI_DynProp_Clu_053 0 "STATIONARY" 1 "MOVING" 2 "AMBIGUIOUS" 3 "RESERVED";
VAL_ 1606 ARS_RDI_Quality_Clu_053 0 "INVALID" 1 "LOW" 2 "MID" 3 "HIGH";
VAL_ 1606 ARS_RDI_DynProp_Clu_054 0 "STATIONARY" 1 "MOVING" 2 "AMBIGUIOUS" 3 "RESERVED";
VAL_ 1606 ARS_RDI_Quality_Clu_054 0 "INVALID" 1 "LOW" 2 "MID" 3 "HIGH";
VAL_ 1606 ARS_RDI_DynProp_Clu_055 0 "STATIONARY" 1 "MOVING" 2 "AMBIGUIOUS" 3 "RESERVED";
VAL_ 1606 ARS_RDI_Quality_Clu_055 0 "INVALID" 1 "LOW" 2 "MID" 3 "HIGH";
VAL_ 1607 ARS_RDI_DynProp_Clu_056 0 "STATIONARY" 1 "MOVING" 2 "AMBIGUIOUS" 3 "RESERVED";
VAL_ 1607 ARS_RDI_Quality_Clu_056 0 "INVALID" 1 "LOW" 2 "MID" 3 "HIGH";
VAL_ 1607 ARS_RDI_DynProp_Clu_057 0 "STATIONARY" 1 "MOVING" 2 "AMBIGUIOUS" 3 "RESERVED";
VAL_ 1607 ARS_RDI_Quality_Clu_057 0 "INVALID" 1 "LOW" 2 "MID" 3 "HIGH";
VAL_ 1607 ARS_RDI_DynProp_Clu_058 0 "STATIONARY" 1 "MOVING" 2 "AMBIGUIOUS" 3 "RESERVED";
VAL_ 1607 ARS_RDI_Quality_Clu_058 0 "INVALID" 1 "LOW" 2 "MID" 3 "HIGH";
VAL_ 1607 ARS_RDI_DynProp_Clu_059 0 "STATIONARY" 1 "MOVING" 2 "AMBIGUIOUS" 3 "RESERVED";
VAL_ 1607 ARS_RDI_Quality_Clu_059 0 "INVALID" 1 "LOW" 2 "MID" 3 "HIGH";
VAL_ 1607 ARS_RDI_DynProp_Clu_060 0 "STATIONARY" 1 "MOVING" 2 "AMBIGUIOUS" 3 "RESERVED";
VAL_ 1607 ARS_RDI_Quality_Clu_060 0 "INVALID" 1 "LOW" 2 "MID" 3 "HIGH";
VAL_ 1607 ARS_RDI_DynProp_Clu_061 0 "STATIONARY" 1 "MOVING" 2 "AMBIGUIOUS" 3 "RESERVED";
VAL_ 1607 ARS_RDI_Quality_Clu_061 0 "INVALID" 1 "LOW" 2 "MID" 3 "HIGH";
VAL_ 1607 ARS_RDI_DynProp_Clu_062 0 "STATIONARY" 1 "MOVING" 2 "AMBIGUIOUS" 3 "RESERVED";
VAL_ 1607 ARS_RDI_Quality_Clu_062 0 "INVALID" 1 "LOW" 2 "MID" 3 "HIGH";
VAL_ 1607 ARS_RDI_DynProp_Clu_063 0 "STATIONARY" 1 "MOVING" 2 "AMBIGUIOUS" 3 "RESERVED";
VAL_ 1607 ARS_RDI_Quality_Clu_063 0 "INVALID" 1 "LOW" 2 "MID" 3 "HIGH";
